VERSION ""

NS_ :

BS_:

BU_: RAND MM5 STMM DD PDM BMS PM VCU
VAL_TABLE_ contactorState 2 "Open" 1 "Close" 0 "Faulted" ;
VAL_TABLE_ vehicleState 8 "Faulted" 7 "ReadyToMove" 6 "Standby" 5 "PrechargeComplete" 4 "PrechargeTimeout" 3 "Precharge" 2 "PrechargeReady" 1 "StartDelay" 0 "Off" ;

BO_ 554 RAND_554: 8 RAND
 SG_ RAND_rateZHor : 32|16@1- (0.02,0) [-655.36|655.34] "degps" Vector__XXX
 SG_ RAND_rateYHor : 16|16@1- (0.02,0) [-655.36|655.34] "degps" Vector__XXX
 SG_ RAND_rateXHor : 0|16@1- (0.02,0) [-655.36|655.34] "degps" Vector__XXX

BO_ 553 RAND_553: 8 RAND
 SG_ RAND_accZHor : 32|16@1- (0.02,0) [-655.36|655.34] "mps2" Vector__XXX
 SG_ RAND_accYHor : 16|16@1- (0.02,0) [-655.36|655.34] "mps2" Vector__XXX
 SG_ RAND_accXHor : 0|16@1- (0.02,0) [-655.36|655.34] "mps2" Vector__XXX

BO_ 552 RAND_552: 8 RAND
 SG_ RAND_pitch : 16|16@1- (0.003,0) [-98.304|98.301] "deg" Vector__XXX
 SG_ RAND_roll : 0|16@1- (0.003,0) [-98.304|98.301] "deg" Vector__XXX

BO_ 551 RAND_551: 8 RAND
 SG_ RAND_accCPoi : 48|16@1- (0.02,0) [-655.36|655.34] "mps2" Vector__XXX
 SG_ RAND_radiusPoi : 32|16@1- (0.01,0) [-327.68|327.67] "m" Vector__XXX
 SG_ RAND_distAPoi : 0|32@1- (0.001,0) [-2147483.648|2147483.647] "m" Vector__XXX

BO_ 550 RAND_550: 8 Vector__XXX
 SG_ RAND_angSPoi : 48|16@1- (0.003,0) [-98.304|98.301] "deg" Vector__XXX
 SG_ RAND_velAPoi : 32|16@1- (0.02,0) [-655.36|655.34] "kph" Vector__XXX
 SG_ RAND_velYPoi : 16|16@1- (0.02,0) [-655.36|655.34] "kph" Vector__XXX
 SG_ RAND_velXPoi : 0|16@1- (0.02,0) [-655.36|655.34] "kph" Vector__XXX

BO_ 501 RAND_501: 8 RAND
 SG_ RAND_postRadPres : 32|16@1- (0.1,0) [-3276.8|3276.7] "kPa" Vector__XXX
 SG_ RAND_postRadTemp : 16|16@1- (0.1,0) [-3276.8|3276.7] "degC" Vector__XXX
 SG_ RAND_counterMsg501 : 0|4@1+ (1,0) [0|15] "" Vector__XXX

BO_ 500 RAND_500: 8 RAND
 SG_ RAND_preRadPres : 32|16@1- (0.1,0) [-3276.8|3276.7] "kPa" Vector__XXX
 SG_ RAND_preRadTemp : 16|16@1- (0.1,0) [-3276.8|3276.7] "degC" Vector__XXX
 SG_ RAND_counterMsg500 : 0|4@1+ (1,0) [0|15] "" Vector__XXX

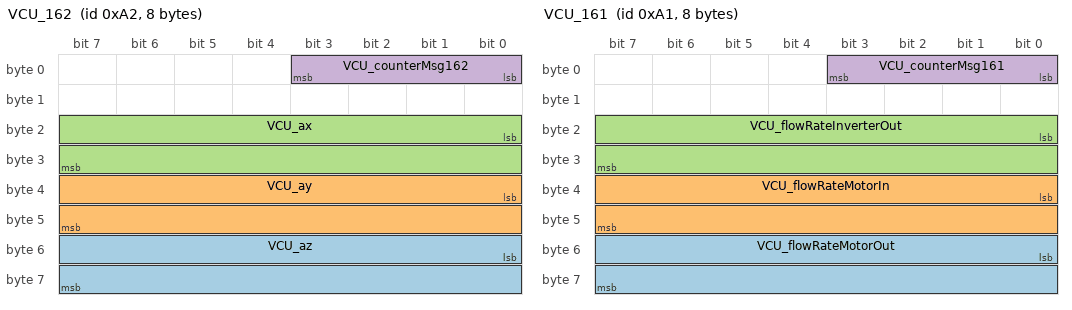
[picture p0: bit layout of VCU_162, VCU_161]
BO_ 162 VCU_162: 8 VCU
 SG_ VCU_az : 48|16@1- (0.001,0) [-32.768|32.767] "g" Vector__XXX
 SG_ VCU_ay : 32|16@1- (0.001,0) [-32.768|32.767] "g" Vector__XXX
 SG_ VCU_ax : 16|16@1- (0.001,0) [-32.768|32.767] "g" Vector__XXX
 SG_ VCU_counterMsg162 : 0|4@1+ (1,0) [0|15] "" Vector__XXX

BO_ 161 VCU_161: 8 VCU
 SG_ VCU_flowRateMotorOut : 48|16@1- (0.1,0) [-3276.8|3276.7] "lpm" Vector__XXX
 SG_ VCU_flowRateMotorIn : 32|16@1- (0.1,0) [-3276.8|3276.7] "lpm" Vector__XXX
 SG_ VCU_flowRateInverterOut : 16|16@1- (0.1,0) [-3276.8|3276.7] "lpm" Vector__XXX
 SG_ VCU_counterMsg161 : 0|4@1+ (1,0) [0|15] "" Vector__XXX

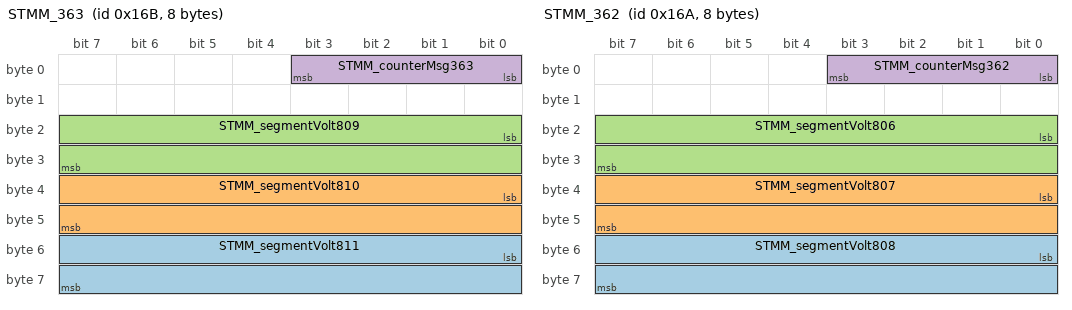
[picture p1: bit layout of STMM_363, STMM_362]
BO_ 363 STMM_363: 8 STMM
 SG_ STMM_segmentVolt811 : 48|16@1- (0.001,0) [-32.768|32.767] "V" Vector__XXX
 SG_ STMM_segmentVolt810 : 32|16@1- (0.001,0) [-32.768|32.767] "V" Vector__XXX
 SG_ STMM_segmentVolt809 : 16|16@1- (0.001,0) [-32.768|32.767] "V" Vector__XXX
 SG_ STMM_counterMsg363 : 0|4@1+ (1,0) [0|15] "" Vector__XXX

BO_ 362 STMM_362: 8 STMM
 SG_ STMM_segmentVolt808 : 48|16@1- (0.001,0) [-32.768|32.767] "V" Vector__XXX
 SG_ STMM_segmentVolt807 : 32|16@1- (0.001,0) [-32.768|32.767] "V" Vector__XXX
 SG_ STMM_segmentVolt806 : 16|16@1- (0.001,0) [-32.768|32.767] "V" Vector__XXX
 SG_ STMM_counterMsg362 : 0|4@1+ (1,0) [0|15] "" Vector__XXX

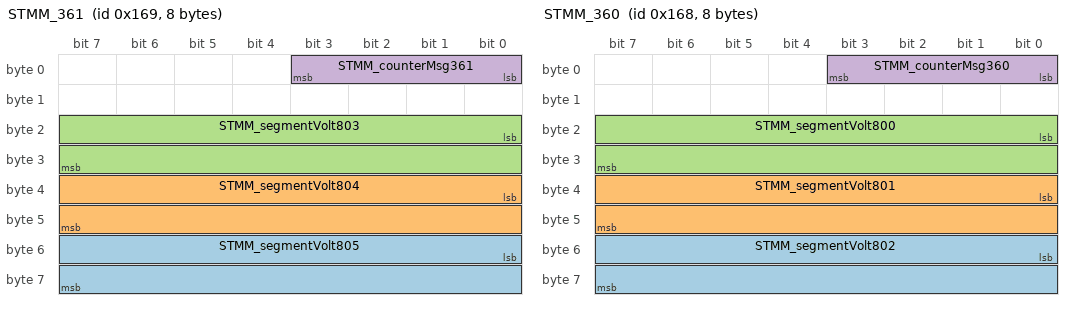
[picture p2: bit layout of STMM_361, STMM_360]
BO_ 361 STMM_361: 8 STMM
 SG_ STMM_segmentVolt805 : 48|16@1- (0.001,0) [-32.768|32.767] "V" Vector__XXX
 SG_ STMM_segmentVolt804 : 32|16@1- (0.001,0) [-32.768|32.767] "V" Vector__XXX
 SG_ STMM_segmentVolt803 : 16|16@1- (0.001,0) [-32.768|32.767] "V" Vector__XXX
 SG_ STMM_counterMsg361 : 0|4@1+ (1,0) [0|15] "" Vector__XXX

BO_ 360 STMM_360: 8 STMM
 SG_ STMM_segmentVolt802 : 48|16@1- (0.001,0) [-32.768|32.767] "V" Vector__XXX
 SG_ STMM_segmentVolt801 : 32|16@1- (0.001,0) [-32.768|32.767] "V" Vector__XXX
 SG_ STMM_segmentVolt800 : 16|16@1- (0.001,0) [-32.768|32.767] "V" Vector__XXX
 SG_ STMM_counterMsg360 : 0|4@1+ (1,0) [0|15] "" Vector__XXX

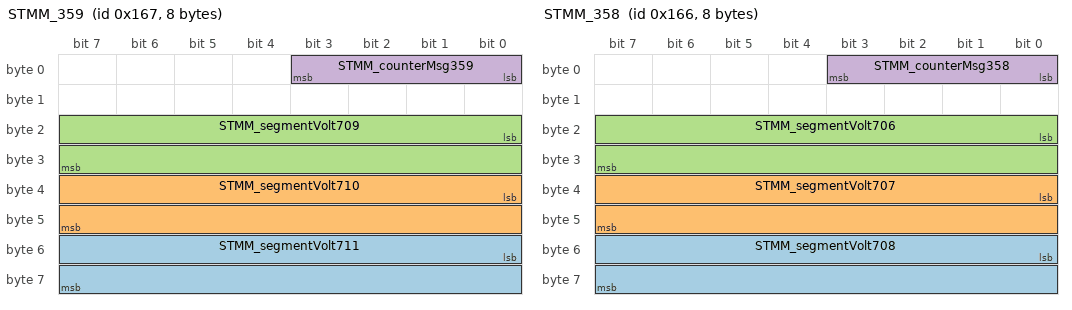
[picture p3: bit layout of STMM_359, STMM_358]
BO_ 359 STMM_359: 8 STMM
 SG_ STMM_segmentVolt711 : 48|16@1- (0.001,0) [-32.768|32.767] "V" Vector__XXX
 SG_ STMM_segmentVolt710 : 32|16@1- (0.001,0) [-32.768|32.767] "V" Vector__XXX
 SG_ STMM_segmentVolt709 : 16|16@1- (0.001,0) [-32.768|32.767] "V" Vector__XXX
 SG_ STMM_counterMsg359 : 0|4@1+ (1,0) [0|15] "" Vector__XXX

BO_ 358 STMM_358: 8 STMM
 SG_ STMM_segmentVolt708 : 48|16@1- (0.001,0) [-32.768|32.767] "V" Vector__XXX
 SG_ STMM_segmentVolt707 : 32|16@1- (0.001,0) [-32.768|32.767] "V" Vector__XXX
 SG_ STMM_segmentVolt706 : 16|16@1- (0.001,0) [-32.768|32.767] "V" Vector__XXX
 SG_ STMM_counterMsg358 : 0|4@1+ (1,0) [0|15] "" Vector__XXX

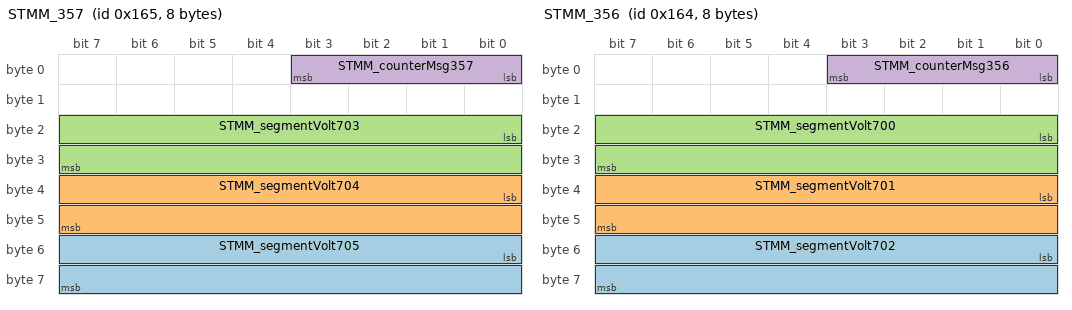
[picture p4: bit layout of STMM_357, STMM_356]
BO_ 357 STMM_357: 8 STMM
 SG_ STMM_segmentVolt705 : 48|16@1- (0.001,0) [-32.768|32.767] "V" Vector__XXX
 SG_ STMM_segmentVolt704 : 32|16@1- (0.001,0) [-32.768|32.767] "V" Vector__XXX
 SG_ STMM_segmentVolt703 : 16|16@1- (0.001,0) [-32.768|32.767] "V" Vector__XXX
 SG_ STMM_counterMsg357 : 0|4@1+ (1,0) [0|15] "" Vector__XXX

BO_ 356 STMM_356: 8 STMM
 SG_ STMM_segmentVolt702 : 48|16@1- (0.001,0) [-32.768|32.767] "V" Vector__XXX
 SG_ STMM_segmentVolt701 : 32|16@1- (0.001,0) [-32.768|32.767] "V" Vector__XXX
 SG_ STMM_segmentVolt700 : 16|16@1- (0.001,0) [-32.768|32.767] "V" Vector__XXX
 SG_ STMM_counterMsg356 : 0|4@1+ (1,0) [0|15] "" Vector__XXX

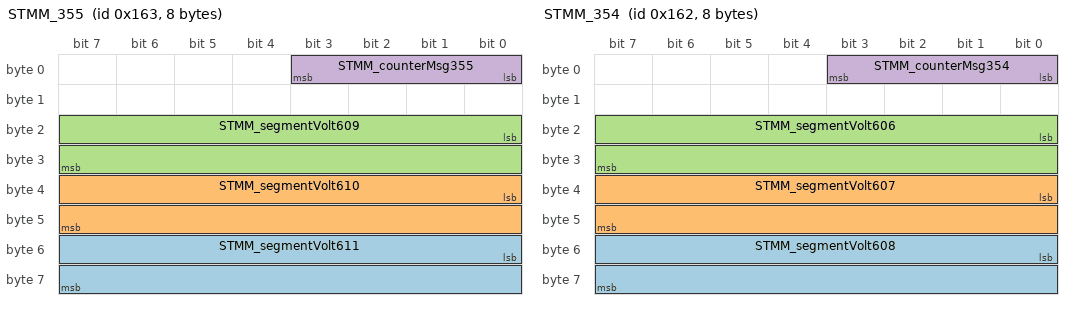
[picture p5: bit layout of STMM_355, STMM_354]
BO_ 355 STMM_355: 8 STMM
 SG_ STMM_segmentVolt611 : 48|16@1- (0.001,0) [-32.768|32.767] "V" Vector__XXX
 SG_ STMM_segmentVolt610 : 32|16@1- (0.001,0) [-32.768|32.767] "V" Vector__XXX
 SG_ STMM_segmentVolt609 : 16|16@1- (0.001,0) [-32.768|32.767] "V" Vector__XXX
 SG_ STMM_counterMsg355 : 0|4@1+ (1,0) [0|15] "" Vector__XXX

BO_ 354 STMM_354: 8 STMM
 SG_ STMM_segmentVolt608 : 48|16@1- (0.001,0) [-32.768|32.767] "V" Vector__XXX
 SG_ STMM_segmentVolt607 : 32|16@1- (0.001,0) [-32.768|32.767] "V" Vector__XXX
 SG_ STMM_segmentVolt606 : 16|16@1- (0.001,0) [-32.768|32.767] "V" Vector__XXX
 SG_ STMM_counterMsg354 : 0|4@1+ (1,0) [0|15] "" Vector__XXX

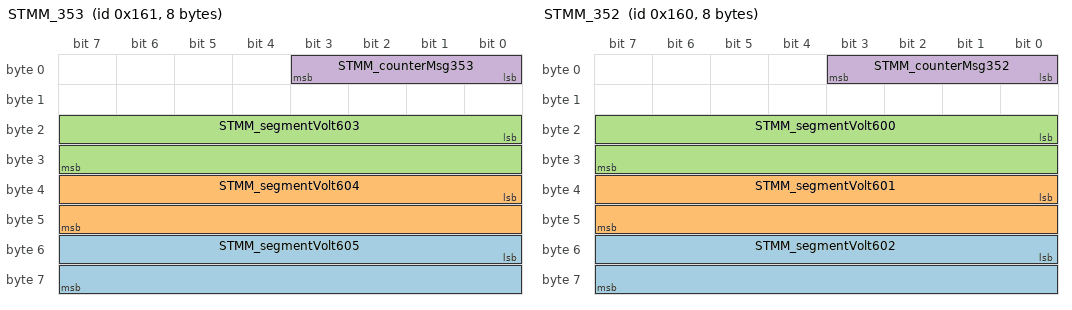
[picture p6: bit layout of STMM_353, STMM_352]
BO_ 353 STMM_353: 8 STMM
 SG_ STMM_segmentVolt605 : 48|16@1- (0.001,0) [-32.768|32.767] "V" Vector__XXX
 SG_ STMM_segmentVolt604 : 32|16@1- (0.001,0) [-32.768|32.767] "V" Vector__XXX
 SG_ STMM_segmentVolt603 : 16|16@1- (0.001,0) [-32.768|32.767] "V" Vector__XXX
 SG_ STMM_counterMsg353 : 0|4@1+ (1,0) [0|15] "" Vector__XXX

BO_ 352 STMM_352: 8 STMM
 SG_ STMM_segmentVolt602 : 48|16@1- (0.001,0) [-32.768|32.767] "V" Vector__XXX
 SG_ STMM_segmentVolt601 : 32|16@1- (0.001,0) [-32.768|32.767] "V" Vector__XXX
 SG_ STMM_segmentVolt600 : 16|16@1- (0.001,0) [-32.768|32.767] "V" Vector__XXX
 SG_ STMM_counterMsg352 : 0|4@1+ (1,0) [0|15] "" Vector__XXX

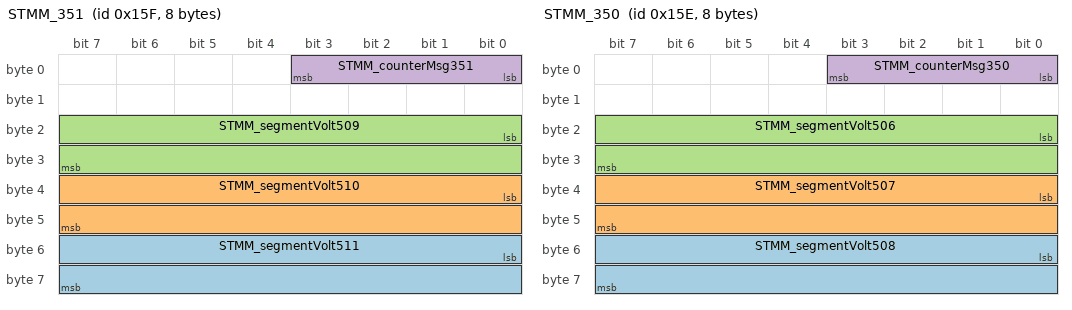
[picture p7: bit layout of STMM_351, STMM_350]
BO_ 351 STMM_351: 8 STMM
 SG_ STMM_segmentVolt511 : 48|16@1- (0.001,0) [-32.768|32.767] "V" Vector__XXX
 SG_ STMM_segmentVolt510 : 32|16@1- (0.001,0) [-32.768|32.767] "V" Vector__XXX
 SG_ STMM_segmentVolt509 : 16|16@1- (0.001,0) [-32.768|32.767] "V" Vector__XXX
 SG_ STMM_counterMsg351 : 0|4@1+ (1,0) [0|15] "" Vector__XXX

BO_ 350 STMM_350: 8 STMM
 SG_ STMM_segmentVolt508 : 48|16@1- (0.001,0) [-32.768|32.767] "V" Vector__XXX
 SG_ STMM_segmentVolt507 : 32|16@1- (0.001,0) [-32.768|32.767] "V" Vector__XXX
 SG_ STMM_segmentVolt506 : 16|16@1- (0.001,0) [-32.768|32.767] "V" Vector__XXX
 SG_ STMM_counterMsg350 : 0|4@1+ (1,0) [0|15] "" Vector__XXX

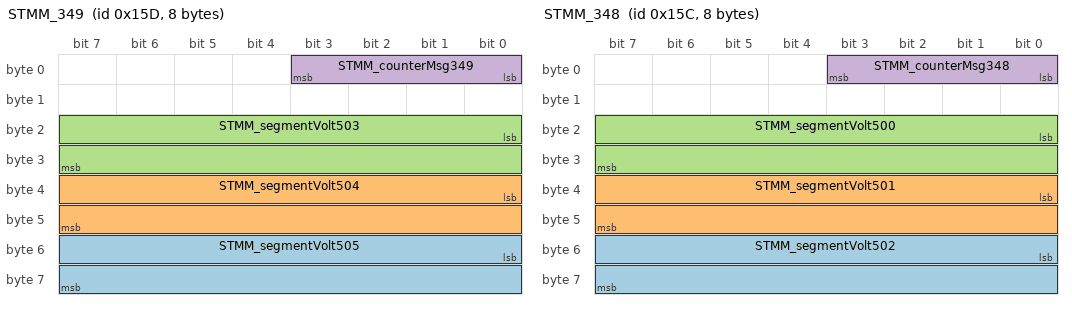
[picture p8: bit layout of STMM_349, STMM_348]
BO_ 349 STMM_349: 8 STMM
 SG_ STMM_segmentVolt505 : 48|16@1- (0.001,0) [-32.768|32.767] "V" Vector__XXX
 SG_ STMM_segmentVolt504 : 32|16@1- (0.001,0) [-32.768|32.767] "V" Vector__XXX
 SG_ STMM_segmentVolt503 : 16|16@1- (0.001,0) [-32.768|32.767] "V" Vector__XXX
 SG_ STMM_counterMsg349 : 0|4@1+ (1,0) [0|15] "" Vector__XXX

BO_ 348 STMM_348: 8 STMM
 SG_ STMM_segmentVolt502 : 48|16@1- (0.001,0) [-32.768|32.767] "V" Vector__XXX
 SG_ STMM_segmentVolt501 : 32|16@1- (0.001,0) [-32.768|32.767] "V" Vector__XXX
 SG_ STMM_segmentVolt500 : 16|16@1- (0.001,0) [-32.768|32.767] "V" Vector__XXX
 SG_ STMM_counterMsg348 : 0|4@1+ (1,0) [0|15] "" Vector__XXX

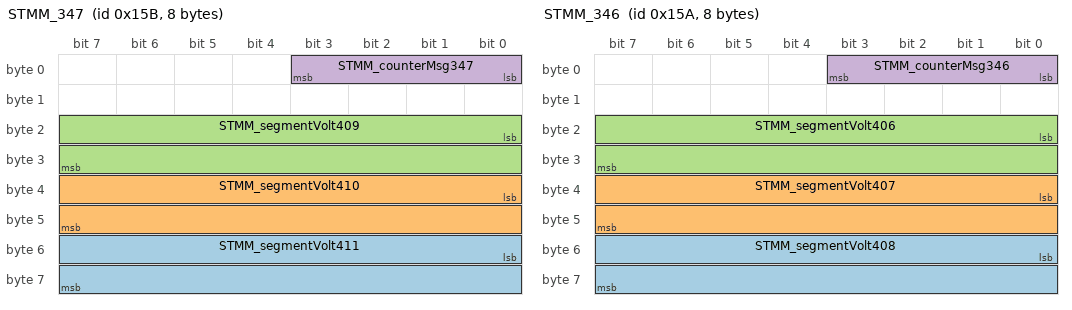
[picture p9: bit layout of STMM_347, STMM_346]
BO_ 347 STMM_347: 8 STMM
 SG_ STMM_segmentVolt411 : 48|16@1- (0.001,0) [-32.768|32.767] "V" Vector__XXX
 SG_ STMM_segmentVolt410 : 32|16@1- (0.001,0) [-32.768|32.767] "V" Vector__XXX
 SG_ STMM_segmentVolt409 : 16|16@1- (0.001,0) [-32.768|32.767] "V" Vector__XXX
 SG_ STMM_counterMsg347 : 0|4@1+ (1,0) [0|15] "" Vector__XXX

BO_ 346 STMM_346: 8 STMM
 SG_ STMM_segmentVolt408 : 48|16@1- (0.001,0) [-32.768|32.767] "V" Vector__XXX
 SG_ STMM_segmentVolt407 : 32|16@1- (0.001,0) [-32.768|32.767] "V" Vector__XXX
 SG_ STMM_segmentVolt406 : 16|16@1- (0.001,0) [-32.768|32.767] "V" Vector__XXX
 SG_ STMM_counterMsg346 : 0|4@1+ (1,0) [0|15] "" Vector__XXX

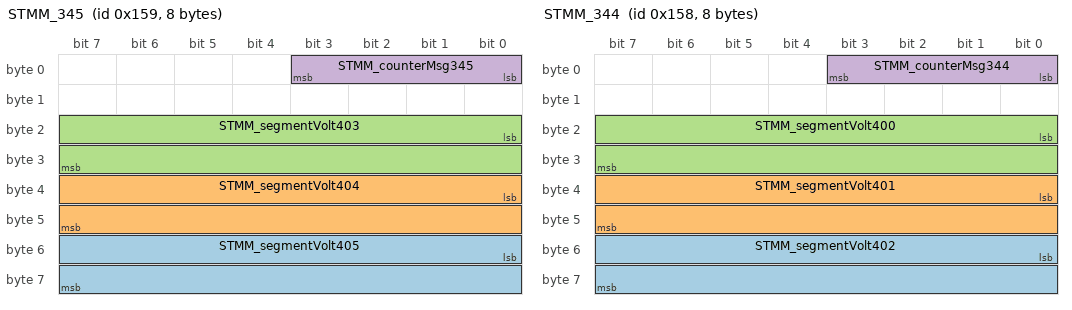
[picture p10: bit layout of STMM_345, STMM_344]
BO_ 345 STMM_345: 8 STMM
 SG_ STMM_segmentVolt405 : 48|16@1- (0.001,0) [-32.768|32.767] "V" Vector__XXX
 SG_ STMM_segmentVolt404 : 32|16@1- (0.001,0) [-32.768|32.767] "V" Vector__XXX
 SG_ STMM_segmentVolt403 : 16|16@1- (0.001,0) [-32.768|32.767] "V" Vector__XXX
 SG_ STMM_counterMsg345 : 0|4@1+ (1,0) [0|15] "" Vector__XXX

BO_ 344 STMM_344: 8 STMM
 SG_ STMM_segmentVolt402 : 48|16@1- (0.001,0) [-32.768|32.767] "V" Vector__XXX
 SG_ STMM_segmentVolt401 : 32|16@1- (0.001,0) [-32.768|32.767] "V" Vector__XXX
 SG_ STMM_segmentVolt400 : 16|16@1- (0.001,0) [-32.768|32.767] "V" Vector__XXX
 SG_ STMM_counterMsg344 : 0|4@1+ (1,0) [0|15] "" Vector__XXX

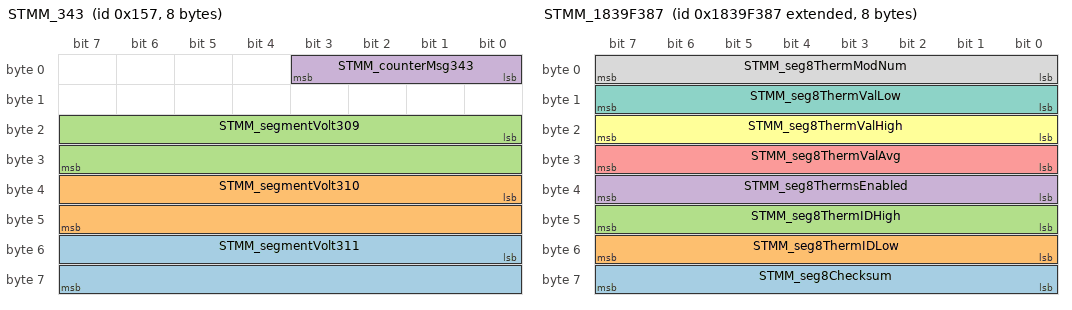
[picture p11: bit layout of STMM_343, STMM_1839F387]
BO_ 343 STMM_343: 8 STMM
 SG_ STMM_segmentVolt311 : 48|16@1- (0.001,0) [-32.768|32.767] "V" Vector__XXX
 SG_ STMM_segmentVolt310 : 32|16@1- (0.001,0) [-32.768|32.767] "V" Vector__XXX
 SG_ STMM_segmentVolt309 : 16|16@1- (0.001,0) [-32.768|32.767] "V" Vector__XXX
 SG_ STMM_counterMsg343 : 0|4@1+ (1,0) [0|15] "" Vector__XXX

BO_ 342 STMM_342: 8 STMM
 SG_ STMM_segmentVolt308 : 48|16@1- (0.001,0) [-32.768|32.767] "V" Vector__XXX
 SG_ STMM_segmentVolt307 : 32|16@1- (0.001,0) [-32.768|32.767] "V" Vector__XXX
 SG_ STMM_segmentVolt306 : 16|16@1- (0.001,0) [-32.768|32.767] "V" Vector__XXX
 SG_ STMM_counterMsg342 : 0|4@1+ (1,0) [0|15] "" Vector__XXX

BO_ 341 STMM_341: 8 STMM
 SG_ STMM_segmentVolt305 : 48|16@1- (0.001,0) [-32.768|32.767] "V" Vector__XXX
 SG_ STMM_segmentVolt304 : 32|16@1- (0.001,0) [-32.768|32.767] "V" Vector__XXX
 SG_ STMM_segmentVolt303 : 16|16@1- (0.001,0) [-32.768|32.767] "V" Vector__XXX
 SG_ STMM_counterMsg341 : 0|4@1+ (1,0) [0|15] "" Vector__XXX

BO_ 340 STMM_340: 8 STMM
 SG_ STMM_segmentVolt302 : 48|16@1- (0.001,0) [-32.768|32.767] "V" Vector__XXX
 SG_ STMM_segmentVolt301 : 32|16@1- (0.001,0) [-32.768|32.767] "V" Vector__XXX
 SG_ STMM_segmentVolt300 : 16|16@1- (0.001,0) [-32.768|32.767] "V" Vector__XXX
 SG_ STMM_counterMsg340 : 0|4@1+ (1,0) [0|15] "" Vector__XXX

BO_ 339 STMM_339: 8 STMM
 SG_ STMM_segmentVolt211 : 48|16@1- (0.001,0) [-32.768|32.767] "V" Vector__XXX
 SG_ STMM_segmentVolt210 : 32|16@1- (0.001,0) [-32.768|32.767] "V" Vector__XXX
 SG_ STMM_segmentVolt209 : 16|16@1- (0.001,0) [-32.768|32.767] "V" Vector__XXX
 SG_ STMM_counterMsg339 : 0|4@1+ (1,0) [0|15] "" Vector__XXX

BO_ 338 STMM_338: 8 STMM
 SG_ STMM_segmentVolt208 : 48|16@1- (0.001,0) [-32.768|32.767] "V" Vector__XXX
 SG_ STMM_segmentVolt207 : 32|16@1- (0.001,0) [-32.768|32.767] "V" Vector__XXX
 SG_ STMM_segmentVolt206 : 16|16@1- (0.001,0) [-32.768|32.767] "V" Vector__XXX
 SG_ STMM_counterMsg338 : 0|4@1+ (1,0) [0|15] "" Vector__XXX

BO_ 337 STMM_337: 8 STMM
 SG_ STMM_segmentVolt205 : 48|16@1- (0.001,0) [-32.768|32.767] "V" Vector__XXX
 SG_ STMM_segmentVolt204 : 32|16@1- (0.001,0) [-32.768|32.767] "V" Vector__XXX
 SG_ STMM_segmentVolt203 : 16|16@1- (0.001,0) [-32.768|32.767] "V" Vector__XXX
 SG_ STMM_counterMsg337 : 0|4@1+ (1,0) [0|15] "" Vector__XXX

BO_ 336 STMM_336: 8 STMM
 SG_ STMM_segmentVolt202 : 48|16@1- (0.001,0) [-32.768|32.767] "V" Vector__XXX
 SG_ STMM_segmentVolt201 : 32|16@1- (0.001,0) [-32.768|32.767] "V" Vector__XXX
 SG_ STMM_segmentVolt200 : 16|16@1- (0.001,0) [-32.768|32.767] "V" Vector__XXX
 SG_ STMM_counterMsg336 : 0|4@1+ (1,0) [0|15] "" Vector__XXX

BO_ 335 STMM_335: 8 STMM
 SG_ STMM_segmentVolt111 : 48|16@1- (0.001,0) [-32.768|32.767] "V" Vector__XXX
 SG_ STMM_segmentVolt110 : 32|16@1- (0.001,0) [-32.768|32.767] "V" Vector__XXX
 SG_ STMM_segmentVolt109 : 16|16@1- (0.001,0) [-32.768|32.767] "V" Vector__XXX
 SG_ STMM_counterMsg335 : 0|4@1+ (1,0) [0|15] "" Vector__XXX

BO_ 334 STMM_334: 8 STMM
 SG_ STMM_segmentVolt108 : 48|16@1- (0.001,0) [-32.768|32.767] "V" Vector__XXX
 SG_ STMM_segmentVolt107 : 32|16@1- (0.001,0) [-32.768|32.767] "V" Vector__XXX
 SG_ STMM_segmentVolt106 : 16|16@1- (0.001,0) [-32.768|32.767] "V" Vector__XXX
 SG_ STMM_counterMsg334 : 0|4@1+ (1,0) [0|15] "" Vector__XXX

BO_ 333 STMM_333: 8 STMM
 SG_ STMM_segmentVolt105 : 48|16@1- (0.001,0) [-32.768|32.767] "V" Vector__XXX
 SG_ STMM_segmentVolt104 : 32|16@1- (0.001,0) [-32.768|32.767] "V" Vector__XXX
 SG_ STMM_segmentVolt103 : 16|16@1- (0.001,0) [-32.768|32.767] "V" Vector__XXX
 SG_ STMM_counterMsg333 : 0|4@1+ (1,0) [0|15] "" Vector__XXX

BO_ 332 STMM_332: 8 STMM
 SG_ STMM_segmentVolt102 : 48|16@1- (0.001,0) [-32.768|32.767] "V" Vector__XXX
 SG_ STMM_segmentVolt101 : 32|16@1- (0.001,0) [-32.768|32.767] "V" Vector__XXX
 SG_ STMM_segmentVolt100 : 16|16@1- (0.001,0) [-32.768|32.767] "V" Vector__XXX
 SG_ STMM_counterMsg332 : 0|4@1+ (1,0) [0|15] "" Vector__XXX

BO_ 299 STMM_299: 8 STMM
 SG_ STMM_counterMsg299 : 0|4@1+ (1,0) [0|15] "" Vector__XXX
 SG_ STMM_segmentSync : 16|8@1+ (1,0) [0|1] "" Vector__XXX

BO_ 160 VCU_160: 8 VCU
 SG_ VCU_driveSpeed : 16|16@1- (0.1,0) [-32768|32767] "mph" Vector__XXX
 SG_ VCU_counterMsg160 : 0|4@1+ (1,0) [0|15] "" Vector__XXX

BO_ 159 VCU_159: 8 VCU
 SG_ VCU_tireTempRRO : 48|16@1- (0.1,0) [-3276.8|3276.7] "degC" Vector__XXX
 SG_ VCU_tireTempRRM : 32|16@1- (0.1,0) [-3276.8|3276.7] "degC" Vector__XXX
 SG_ VCU_tireTempRRI : 16|16@1- (0.1,0) [-3276.8|3276.7] "degC" Vector__XXX
 SG_ VCU_counterMsg159 : 0|4@1+ (1,0) [0|15] "" Vector__XXX

BO_ 158 VCU_158: 8 VCU
 SG_ VCU_tireTempRLO : 48|16@1- (0.1,0) [-3276.8|3276.7] "degC" Vector__XXX
 SG_ VCU_tireTempRLM : 32|16@1- (0.1,0) [-3276.8|3276.7] "degC" Vector__XXX
 SG_ VCU_tireTempRLI : 16|16@1- (0.1,0) [-3276.8|3276.7] "degC" Vector__XXX
 SG_ VCU_counterMsg158 : 0|4@1+ (1,0) [0|15] "" Vector__XXX

BO_ 157 VCU_157: 8 VCU
 SG_ VCU_tireTempFRO : 48|16@1- (0.1,0) [-3276.8|3276.7] "degC" Vector__XXX
 SG_ VCU_tireTempFRM : 32|16@1- (0.1,0) [-3276.8|3276.7] "degC" Vector__XXX
 SG_ VCU_tireTempFRI : 16|16@1- (0.1,0) [-3276.8|3276.7] "degC" Vector__XXX
 SG_ VCU_counterMsg157 : 0|4@1+ (1,0) [0|15] "" Vector__XXX

BO_ 156 VCU_156: 8 VCU
 SG_ VCU_tireTempFLO : 48|16@1- (0.1,0) [-3276.8|3276.7] "degC" Vector__XXX
 SG_ VCU_tireTempFLM : 32|16@1- (0.1,0) [-3276.8|3276.7] "degC" Vector__XXX
 SG_ VCU_tireTempFLI : 16|16@1- (0.1,0) [-3276.8|3276.7] "degC" Vector__XXX
 SG_ VCU_counterMsg156 : 0|4@1+ (1,0) [0|15] "" Vector__XXX

BO_ 155 VCU_155: 8 VCU
 SG_ VCU_rotorTempRR : 32|16@1- (0.1,0) [-3276.8|3276.7] "degC" Vector__XXX
 SG_ VCU_rotorTempRL : 16|16@1- (0.1,0) [-3276.8|3276.7] "degC" Vector__XXX
 SG_ VCU_counterMsg155 : 0|4@1+ (1,0) [0|15] "" Vector__XXX

BO_ 154 VCU_154: 8 VCU
 SG_ VCU_rotorTempFR : 32|16@1- (0.1,0) [-3276.8|3276.7] "degC" Vector__XXX
 SG_ VCU_rotorTempFL : 16|16@1- (0.1,0) [-3276.8|3276.7] "degC" Vector__XXX
 SG_ VCU_counterMsg154 : 0|4@1+ (1,0) [0|15] "" Vector__XXX

BO_ 2553934727 STMM_1839F387: 8 STMM
 SG_ STMM_seg8Checksum : 56|8@1+ (1,0) [0|255] "" Vector__XXX
 SG_ STMM_seg8ThermIDLow : 48|8@1+ (1,0) [0|255] "" Vector__XXX
 SG_ STMM_seg8ThermIDHigh : 40|8@1+ (1,0) [0|255] "" Vector__XXX
 SG_ STMM_seg8ThermsEnabled : 32|8@1+ (1,0) [0|255] "" Vector__XXX
 SG_ STMM_seg8ThermValAvg : 24|8@1- (1,0) [-128|127] "degC" Vector__XXX
 SG_ STMM_seg8ThermValHigh : 16|8@1- (1,0) [-128|127] "degC" Vector__XXX
 SG_ STMM_seg8ThermValLow : 8|8@1- (1,0) [-128|127] "degC" Vector__XXX
 SG_ STMM_seg8ThermModNum : 0|8@1+ (1,0) [0|255] "" Vector__XXX

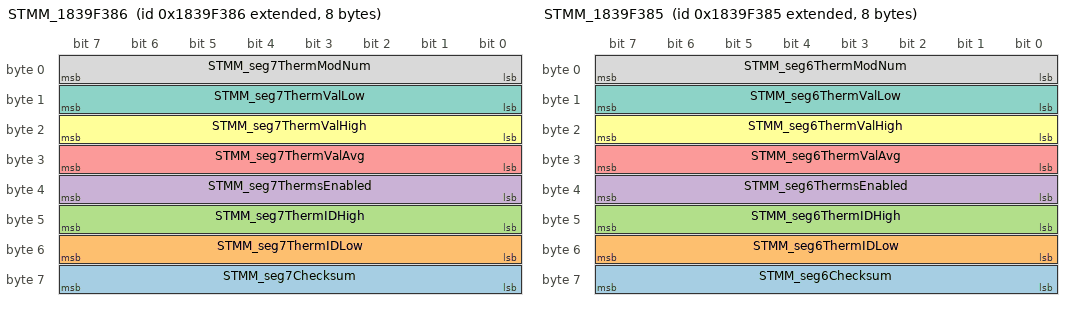
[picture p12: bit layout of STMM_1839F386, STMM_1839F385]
BO_ 2553934726 STMM_1839F386: 8 STMM
 SG_ STMM_seg7Checksum : 56|8@1+ (1,0) [0|255] "" Vector__XXX
 SG_ STMM_seg7ThermIDLow : 48|8@1+ (1,0) [0|255] "" Vector__XXX
 SG_ STMM_seg7ThermIDHigh : 40|8@1+ (1,0) [0|255] "" Vector__XXX
 SG_ STMM_seg7ThermsEnabled : 32|8@1+ (1,0) [0|255] "" Vector__XXX
 SG_ STMM_seg7ThermValAvg : 24|8@1- (1,0) [-128|127] "degC" Vector__XXX
 SG_ STMM_seg7ThermValHigh : 16|8@1- (1,0) [-128|127] "degC" Vector__XXX
 SG_ STMM_seg7ThermValLow : 8|8@1- (1,0) [-128|127] "degC" Vector__XXX
 SG_ STMM_seg7ThermModNum : 0|8@1+ (1,0) [0|255] "" Vector__XXX

BO_ 2553934725 STMM_1839F385: 8 STMM
 SG_ STMM_seg6Checksum : 56|8@1+ (1,0) [0|255] "" Vector__XXX
 SG_ STMM_seg6ThermIDLow : 48|8@1+ (1,0) [0|255] "" Vector__XXX
 SG_ STMM_seg6ThermIDHigh : 40|8@1+ (1,0) [0|255] "" Vector__XXX
 SG_ STMM_seg6ThermsEnabled : 32|8@1+ (1,0) [0|255] "" Vector__XXX
 SG_ STMM_seg6ThermValAvg : 24|8@1- (1,0) [-128|127] "degC" Vector__XXX
 SG_ STMM_seg6ThermValHigh : 16|8@1- (1,0) [-128|127] "degC" Vector__XXX
 SG_ STMM_seg6ThermValLow : 8|8@1- (1,0) [-128|127] "degC" Vector__XXX
 SG_ STMM_seg6ThermModNum : 0|8@1+ (1,0) [0|255] "" Vector__XXX

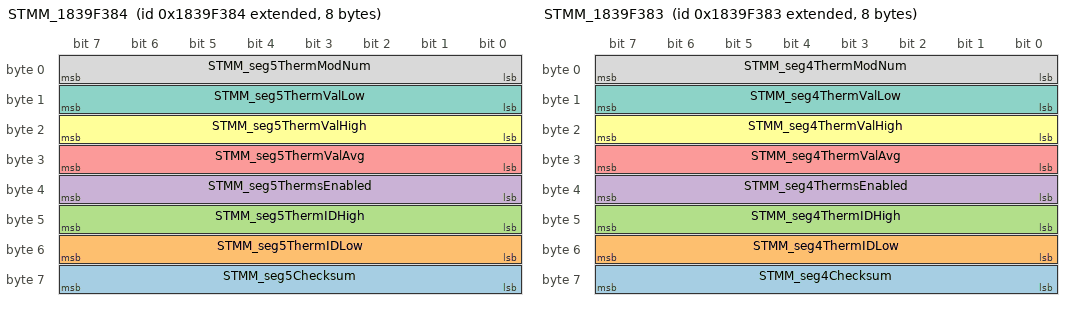
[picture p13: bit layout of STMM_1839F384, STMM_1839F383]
BO_ 2553934724 STMM_1839F384: 8 STMM
 SG_ STMM_seg5Checksum : 56|8@1+ (1,0) [0|255] "" Vector__XXX
 SG_ STMM_seg5ThermIDLow : 48|8@1+ (1,0) [0|255] "" Vector__XXX
 SG_ STMM_seg5ThermIDHigh : 40|8@1+ (1,0) [0|255] "" Vector__XXX
 SG_ STMM_seg5ThermsEnabled : 32|8@1+ (1,0) [0|255] "" Vector__XXX
 SG_ STMM_seg5ThermValAvg : 24|8@1- (1,0) [-128|127] "degC" Vector__XXX
 SG_ STMM_seg5ThermValHigh : 16|8@1- (1,0) [-128|127] "degC" Vector__XXX
 SG_ STMM_seg5ThermValLow : 8|8@1- (1,0) [-128|127] "degC" Vector__XXX
 SG_ STMM_seg5ThermModNum : 0|8@1+ (1,0) [0|255] "" Vector__XXX

BO_ 2553934723 STMM_1839F383: 8 STMM
 SG_ STMM_seg4Checksum : 56|8@1+ (1,0) [0|255] "" Vector__XXX
 SG_ STMM_seg4ThermIDLow : 48|8@1+ (1,0) [0|255] "" Vector__XXX
 SG_ STMM_seg4ThermIDHigh : 40|8@1+ (1,0) [0|255] "" Vector__XXX
 SG_ STMM_seg4ThermsEnabled : 32|8@1+ (1,0) [0|255] "" Vector__XXX
 SG_ STMM_seg4ThermValAvg : 24|8@1- (1,0) [-128|127] "degC" Vector__XXX
 SG_ STMM_seg4ThermValHigh : 16|8@1- (1,0) [-128|127] "degC" Vector__XXX
 SG_ STMM_seg4ThermValLow : 8|8@1- (1,0) [-128|127] "degC" Vector__XXX
 SG_ STMM_seg4ThermModNum : 0|8@1+ (1,0) [0|255] "" Vector__XXX

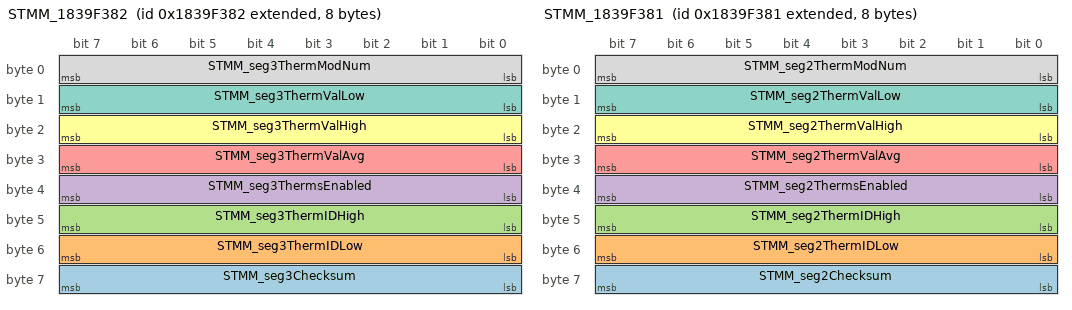
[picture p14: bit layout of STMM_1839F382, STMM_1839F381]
BO_ 2553934722 STMM_1839F382: 8 STMM
 SG_ STMM_seg3Checksum : 56|8@1+ (1,0) [0|255] "" Vector__XXX
 SG_ STMM_seg3ThermIDLow : 48|8@1+ (1,0) [0|255] "" Vector__XXX
 SG_ STMM_seg3ThermIDHigh : 40|8@1+ (1,0) [0|255] "" Vector__XXX
 SG_ STMM_seg3ThermsEnabled : 32|8@1+ (1,0) [0|255] "" Vector__XXX
 SG_ STMM_seg3ThermValAvg : 24|8@1- (1,0) [-128|127] "degC" Vector__XXX
 SG_ STMM_seg3ThermValHigh : 16|8@1- (1,0) [-128|127] "degC" Vector__XXX
 SG_ STMM_seg3ThermValLow : 8|8@1- (1,0) [-128|127] "degC" Vector__XXX
 SG_ STMM_seg3ThermModNum : 0|8@1+ (1,0) [0|255] "" Vector__XXX

BO_ 2553934721 STMM_1839F381: 8 STMM
 SG_ STMM_seg2Checksum : 56|8@1+ (1,0) [0|255] "" Vector__XXX
 SG_ STMM_seg2ThermIDLow : 48|8@1+ (1,0) [0|255] "" Vector__XXX
 SG_ STMM_seg2ThermIDHigh : 40|8@1+ (1,0) [0|255] "" Vector__XXX
 SG_ STMM_seg2ThermsEnabled : 32|8@1+ (1,0) [0|255] "" Vector__XXX
 SG_ STMM_seg2ThermValAvg : 24|8@1- (1,0) [-128|127] "degC" Vector__XXX
 SG_ STMM_seg2ThermValHigh : 16|8@1- (1,0) [-128|127] "degC" Vector__XXX
 SG_ STMM_seg2ThermValLow : 8|8@1- (1,0) [-128|127] "degC" Vector__XXX
 SG_ STMM_seg2ThermModNum : 0|8@1+ (1,0) [0|255] "" Vector__XXX

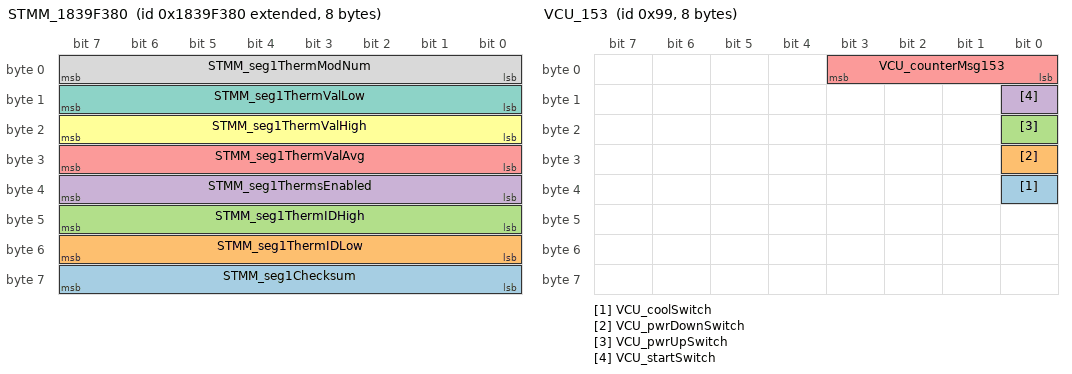
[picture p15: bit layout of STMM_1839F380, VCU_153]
BO_ 2553934720 STMM_1839F380: 8 STMM
 SG_ STMM_seg1Checksum : 56|8@1+ (1,0) [0|255] "" Vector__XXX
 SG_ STMM_seg1ThermIDLow : 48|8@1+ (1,0) [0|255] "" Vector__XXX
 SG_ STMM_seg1ThermIDHigh : 40|8@1+ (1,0) [0|255] "" Vector__XXX
 SG_ STMM_seg1ThermsEnabled : 32|8@1+ (1,0) [0|255] "" Vector__XXX
 SG_ STMM_seg1ThermValAvg : 24|8@1- (1,0) [-128|127] "degC" Vector__XXX
 SG_ STMM_seg1ThermValHigh : 16|8@1- (1,0) [-128|127] "degC" Vector__XXX
 SG_ STMM_seg1ThermValLow : 8|8@1- (1,0) [-128|127] "degC" Vector__XXX
 SG_ STMM_seg1ThermModNum : 0|8@1+ (1,0) [0|255] "" Vector__XXX

BO_ 153 VCU_153: 8 VCU
 SG_ VCU_coolSwitch : 32|1@1+ (1,0) [0|1] "" Vector__XXX
 SG_ VCU_pwrDownSwitch : 24|1@1+ (1,0) [0|1] "" Vector__XXX
 SG_ VCU_pwrUpSwitch : 16|1@1+ (1,0) [0|1] "" Vector__XXX
 SG_ VCU_startSwitch : 8|1@1+ (1,0) [0|1] "" Vector__XXX
 SG_ VCU_counterMsg153 : 0|4@1+ (1,0) [0|15] "" Vector__XXX

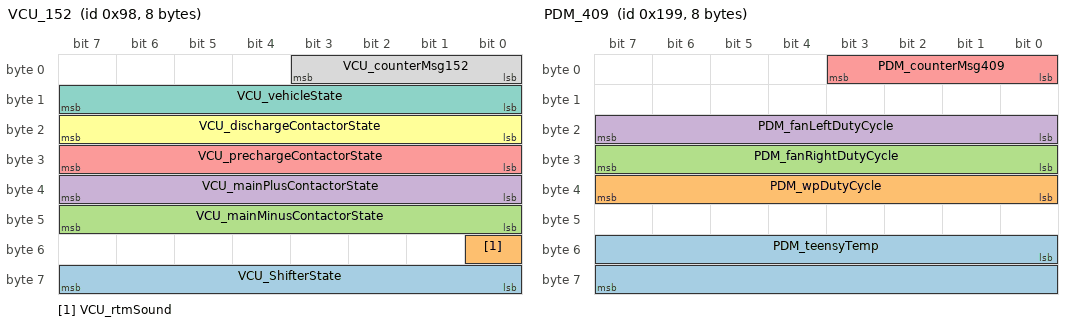
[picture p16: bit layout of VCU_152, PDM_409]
BO_ 152 VCU_152: 8 VCU
 SG_ VCU_ShifterState : 56|8@1+ (1,0) [0|255] "" Vector__XXX
 SG_ VCU_rtmSound : 48|1@1+ (1,0) [0|1] "" Vector__XXX
 SG_ VCU_mainMinusContactorState : 40|8@1+ (1,0) [0|255] "" Vector__XXX
 SG_ VCU_mainPlusContactorState : 32|8@1+ (1,0) [0|255] "" Vector__XXX
 SG_ VCU_prechargeContactorState : 24|8@1+ (1,0) [0|255] "" Vector__XXX
 SG_ VCU_dischargeContactorState : 16|8@1+ (1,0) [0|255] "" Vector__XXX
 SG_ VCU_vehicleState : 8|8@1+ (1,0) [0|255] "" Vector__XXX
 SG_ VCU_counterMsg152 : 0|4@1+ (1,0) [0|15] "" Vector__XXX

BO_ 151 VCU_151: 8 VCU
 SG_ VCU_brakePressureR : 48|16@1- (0.1,0) [0|2000] "psi" Vector__XXX
 SG_ VCU_brakePressureF : 32|16@1- (0.1,0) [0|2000] "psi" Vector__XXX
 SG_ VCU_brakeBias : 16|16@1- (0.1,0) [-3276.8|3276.7] "%" Vector__XXX
 SG_ VCU_counterMsg151 : 0|4@1+ (1,0) [0|15] "" Vector__XXX

BO_ 380 MM5_380: 8 MM5
 SG_ MM5_az : 32|16@1+ (-0.0001274,4.1745795) [-4.1745795|4.1745795] "g" Vector__XXX

BO_ 376 MM5_376: 8 MM5
 SG_ MM5_rollRate : 0|16@1+ (-0.005,163.9) [-163.775|163.9] "deg/s" Vector__XXX
 SG_ MM5_ax : 32|16@1+ (-0.0001274,4.1745795) [-4.1745795|4.1745795] "g" Vector__XXX

BO_ 372 MM5_372: 8 MM5
 SG_ MM5_yawRate : 0|16@1+ (0.005,-163.9) [-163.9|163.775] "deg/s" Vector__XXX
 SG_ MM5_ay : 32|16@1+ (0.0001274,-4.1745795) [-4.1745795|4.1745795] "g" Vector__XXX

BO_ 331 STMM_331: 8 STMM
 SG_ STMM_segmentTemp811 : 48|16@1- (0.1,0) [-5|120] "degC" Vector__XXX
 SG_ STMM_segmentTemp810 : 32|16@1- (0.1,0) [-5|120] "degC" Vector__XXX
 SG_ STMM_segmentTemp809 : 16|16@1- (0.1,0) [-5|120] "degC" Vector__XXX
 SG_ STMM_counterMsg331 : 0|4@1+ (1,0) [0|15] "" Vector__XXX

BO_ 330 STMM_330: 8 STMM
 SG_ STMM_segmentTemp808 : 48|16@1- (0.1,0) [-5|120] "degC" Vector__XXX
 SG_ STMM_segmentTemp807 : 32|16@1- (0.1,0) [-5|120] "degC" Vector__XXX
 SG_ STMM_segmentTemp806 : 16|16@1- (0.1,0) [-5|120] "degC" Vector__XXX
 SG_ STMM_counterMsg330 : 0|4@1+ (1,0) [0|15] "" Vector__XXX

BO_ 329 STMM_329: 8 STMM
 SG_ STMM_segmentTemp805 : 48|16@1- (0.1,0) [-5|120] "degC" Vector__XXX
 SG_ STMM_segmentTemp804 : 32|16@1- (0.1,0) [-5|120] "degC" Vector__XXX
 SG_ STMM_segmentTemp803 : 16|16@1- (0.1,0) [-5|120] "degC" Vector__XXX
 SG_ STMM_counterMsg329 : 0|4@1+ (1,0) [0|15] "" Vector__XXX

BO_ 328 STMM_328: 8 STMM
 SG_ STMM_segmentTemp802 : 48|16@1- (0.1,0) [-5|120] "degC" Vector__XXX
 SG_ STMM_segmentTemp801 : 32|16@1- (0.1,0) [-5|120] "degC" Vector__XXX
 SG_ STMM_segmentTemp800 : 16|16@1- (0.1,0) [-5|120] "degC" Vector__XXX
 SG_ STMM_counterMsg328 : 0|4@1+ (1,0) [0|15] "" Vector__XXX

BO_ 327 STMM_327: 8 STMM
 SG_ STMM_segmentTemp711 : 48|16@1- (0.1,0) [-5|120] "degC" Vector__XXX
 SG_ STMM_segmentTemp710 : 32|16@1- (0.1,0) [-5|120] "degC" Vector__XXX
 SG_ STMM_segmentTemp709 : 16|16@1- (0.1,0) [-5|120] "degC" Vector__XXX
 SG_ STMM_counterMsg327 : 0|4@1+ (1,0) [0|15] "" Vector__XXX

BO_ 326 STMM_326: 8 STMM
 SG_ STMM_segmentTemp708 : 48|16@1- (0.1,0) [-5|120] "degC" Vector__XXX
 SG_ STMM_segmentTemp707 : 32|16@1- (0.1,0) [-5|120] "degC" Vector__XXX
 SG_ STMM_segmentTemp706 : 16|16@1- (0.1,0) [-5|120] "degC" Vector__XXX
 SG_ STMM_counterMsg326 : 0|4@1+ (1,0) [0|15] "" Vector__XXX

BO_ 325 STMM_325: 8 STMM
 SG_ STMM_segmentTemp705 : 48|16@1- (0.1,0) [-5|120] "degC" Vector__XXX
 SG_ STMM_segmentTemp704 : 32|16@1- (0.1,0) [-5|120] "degC" Vector__XXX
 SG_ STMM_segmentTemp703 : 16|16@1- (0.1,0) [-5|120] "degC" Vector__XXX
 SG_ STMM_counterMsg325 : 0|4@1+ (1,0) [0|15] "" Vector__XXX

BO_ 324 STMM_324: 8 STMM
 SG_ STMM_segmentTemp702 : 48|16@1- (0.1,0) [-5|120] "degC" Vector__XXX
 SG_ STMM_segmentTemp701 : 32|16@1- (0.1,0) [-5|120] "degC" Vector__XXX
 SG_ STMM_segmentTemp700 : 16|16@1- (0.1,0) [-5|120] "degC" Vector__XXX
 SG_ STMM_counterMsg324 : 0|4@1+ (1,0) [0|15] "" Vector__XXX

BO_ 323 STMM_323: 8 STMM
 SG_ STMM_segmentTemp611 : 48|16@1- (0.1,0) [-5|120] "degC" Vector__XXX
 SG_ STMM_segmentTemp610 : 32|16@1- (0.1,0) [-5|120] "degC" Vector__XXX
 SG_ STMM_segmentTemp609 : 16|16@1- (0.1,0) [-5|120] "degC" Vector__XXX
 SG_ STMM_counterMsg323 : 0|4@1+ (1,0) [0|15] "" Vector__XXX

BO_ 322 STMM_322: 8 STMM
 SG_ STMM_segmentTemp608 : 48|16@1- (0.1,0) [-5|120] "degC" Vector__XXX
 SG_ STMM_segmentTemp607 : 32|16@1- (0.1,0) [-5|120] "degC" Vector__XXX
 SG_ STMM_segmentTemp606 : 16|16@1- (0.1,0) [-5|120] "degC" Vector__XXX
 SG_ STMM_counterMsg322 : 0|4@1+ (1,0) [0|15] "" Vector__XXX

BO_ 321 STMM_321: 8 STMM
 SG_ STMM_segmentTemp605 : 48|16@1- (0.1,0) [-5|120] "degC" Vector__XXX
 SG_ STMM_segmentTemp604 : 32|16@1- (0.1,0) [-5|120] "degC" Vector__XXX
 SG_ STMM_segmentTemp603 : 16|16@1- (0.1,0) [-5|120] "degC" Vector__XXX
 SG_ STMM_counterMsg321 : 0|4@1+ (1,0) [0|15] "" Vector__XXX

BO_ 320 STMM_320: 8 STMM
 SG_ STMM_segmentTemp602 : 48|16@1- (0.1,0) [-5|120] "degC" Vector__XXX
 SG_ STMM_segmentTemp601 : 32|16@1- (0.1,0) [-5|120] "degC" Vector__XXX
 SG_ STMM_segmentTemp600 : 16|16@1- (0.1,0) [-5|120] "degC" Vector__XXX
 SG_ STMM_counterMsg320 : 0|4@1+ (1,0) [0|15] "" Vector__XXX

BO_ 319 STMM_319: 8 STMM
 SG_ STMM_segmentTemp511 : 48|16@1- (0.1,0) [-5|120] "degC" Vector__XXX
 SG_ STMM_segmentTemp510 : 32|16@1- (0.1,0) [-5|120] "degC" Vector__XXX
 SG_ STMM_segmentTemp509 : 16|16@1- (0.1,0) [-5|120] "degC" Vector__XXX
 SG_ STMM_counterMsg319 : 0|4@1+ (1,0) [0|15] "" Vector__XXX

BO_ 318 STMM_318: 8 STMM
 SG_ STMM_segmentTemp508 : 48|16@1- (0.1,0) [-5|120] "degC" Vector__XXX
 SG_ STMM_segmentTemp507 : 32|16@1- (0.1,0) [-5|120] "degC" Vector__XXX
 SG_ STMM_segmentTemp506 : 16|16@1- (0.1,0) [-5|120] "degC" Vector__XXX
 SG_ STMM_counterMsg318 : 0|4@1+ (1,0) [0|15] "" Vector__XXX

BO_ 317 STMM_317: 8 STMM
 SG_ STMM_segmentTemp505 : 48|16@1- (0.1,0) [-5|120] "degC" Vector__XXX
 SG_ STMM_segmentTemp504 : 32|16@1- (0.1,0) [-5|120] "degC" Vector__XXX
 SG_ STMM_segmentTemp503 : 16|16@1- (0.1,0) [-5|120] "degC" Vector__XXX
 SG_ STMM_counterMsg317 : 0|4@1+ (1,0) [0|15] "" Vector__XXX

BO_ 316 STMM_316: 8 STMM
 SG_ STMM_segmentTemp502 : 48|16@1- (0.1,0) [-5|120] "degC" Vector__XXX
 SG_ STMM_segmentTemp501 : 32|16@1- (0.1,0) [-5|120] "degC" Vector__XXX
 SG_ STMM_segmentTemp500 : 16|16@1- (0.1,0) [-5|120] "degC" Vector__XXX
 SG_ STMM_counterMsg316 : 0|4@1+ (1,0) [0|15] "" Vector__XXX

BO_ 315 STMM_315: 8 STMM
 SG_ STMM_segmentTemp411 : 48|16@1- (0.1,0) [-5|120] "degC" Vector__XXX
 SG_ STMM_segmentTemp410 : 32|16@1- (0.1,0) [-5|120] "degC" Vector__XXX
 SG_ STMM_segmentTemp409 : 16|16@1- (0.1,0) [-5|120] "degC" Vector__XXX
 SG_ STMM_counterMsg315 : 0|4@1+ (1,0) [0|15] "" Vector__XXX

BO_ 314 STMM_314: 8 STMM
 SG_ STMM_segmentTemp408 : 48|16@1- (0.1,0) [-5|120] "degC" Vector__XXX
 SG_ STMM_segmentTemp407 : 32|16@1- (0.1,0) [-5|120] "degC" Vector__XXX
 SG_ STMM_segmentTemp406 : 16|16@1- (0.1,0) [-5|120] "degC" Vector__XXX
 SG_ STMM_counterMsg314 : 0|4@1+ (1,0) [0|15] "" Vector__XXX

BO_ 313 STMM_313: 8 STMM
 SG_ STMM_segmentTemp405 : 48|16@1- (0.1,0) [-5|120] "degC" Vector__XXX
 SG_ STMM_segmentTemp404 : 32|16@1- (0.1,0) [-5|120] "degC" Vector__XXX
 SG_ STMM_segmentTemp403 : 16|16@1- (0.1,0) [-5|120] "degC" Vector__XXX
 SG_ STMM_counterMsg313 : 0|4@1+ (1,0) [0|15] "" Vector__XXX

BO_ 312 STMM_312: 8 STMM
 SG_ STMM_segmentTemp402 : 48|16@1- (0.1,0) [-5|120] "degC" Vector__XXX
 SG_ STMM_segmentTemp401 : 32|16@1- (0.1,0) [-5|120] "degC" Vector__XXX
 SG_ STMM_segmentTemp400 : 16|16@1- (0.1,0) [-5|120] "degC" Vector__XXX
 SG_ STMM_counterMsg312 : 0|4@1+ (1,0) [0|15] "" Vector__XXX

BO_ 311 STMM_311: 8 STMM
 SG_ STMM_segmentTemp311 : 48|16@1- (0.1,0) [-5|120] "degC" Vector__XXX
 SG_ STMM_segmentTemp310 : 32|16@1- (0.1,0) [-5|120] "degC" Vector__XXX
 SG_ STMM_segmentTemp309 : 16|16@1- (0.1,0) [-5|120] "degC" Vector__XXX
 SG_ STMM_counterMsg311 : 0|4@1+ (1,0) [0|15] "" Vector__XXX

BO_ 310 STMM_310: 8 STMM
 SG_ STMM_segmentTemp308 : 48|16@1- (0.1,0) [-5|120] "degC" Vector__XXX
 SG_ STMM_segmentTemp307 : 32|16@1- (0.1,0) [-5|120] "degC" Vector__XXX
 SG_ STMM_segmentTemp306 : 16|16@1- (0.1,0) [-5|120] "degC" Vector__XXX
 SG_ STMM_counterMsg310 : 0|4@1+ (1,0) [0|15] "" Vector__XXX

BO_ 309 STMM_309: 8 STMM
 SG_ STMM_segmentTemp305 : 48|16@1- (0.1,0) [-5|120] "degC" Vector__XXX
 SG_ STMM_segmentTemp304 : 32|16@1- (0.1,0) [-5|120] "degC" Vector__XXX
 SG_ STMM_segmentTemp303 : 16|16@1- (0.1,0) [-5|120] "degC" Vector__XXX
 SG_ STMM_counterMsg309 : 0|4@1+ (1,0) [0|15] "" Vector__XXX

BO_ 308 STMM_308: 8 STMM
 SG_ STMM_segmentTemp302 : 48|16@1- (0.1,0) [-5|120] "degC" Vector__XXX
 SG_ STMM_segmentTemp301 : 32|16@1- (0.1,0) [-5|120] "degC" Vector__XXX
 SG_ STMM_segmentTemp300 : 16|16@1- (0.1,0) [-5|120] "degC" Vector__XXX
 SG_ STMM_counterMsg308 : 0|4@1+ (1,0) [0|15] "" Vector__XXX

BO_ 307 STMM_307: 8 STMM
 SG_ STMM_segmentTemp211 : 48|16@1- (0.1,0) [-5|120] "degC" Vector__XXX
 SG_ STMM_segmentTemp210 : 32|16@1- (0.1,0) [-5|120] "degC" Vector__XXX
 SG_ STMM_segmentTemp209 : 16|16@1- (0.1,0) [-5|120] "degC" Vector__XXX
 SG_ STMM_counterMsg307 : 0|4@1+ (1,0) [0|15] "" Vector__XXX

BO_ 306 STMM_306: 8 STMM
 SG_ STMM_segmentTemp208 : 48|16@1- (0.1,0) [-5|120] "degC" Vector__XXX
 SG_ STMM_segmentTemp207 : 32|16@1- (0.1,0) [-5|120] "degC" Vector__XXX
 SG_ STMM_segmentTemp206 : 16|16@1- (0.1,0) [-5|120] "degC" Vector__XXX
 SG_ STMM_counterMsg306 : 0|4@1+ (1,0) [0|15] "" Vector__XXX

BO_ 305 STMM_305: 8 STMM
 SG_ STMM_segmentTemp205 : 48|16@1- (0.1,0) [-5|120] "degC" Vector__XXX
 SG_ STMM_segmentTemp204 : 32|16@1- (0.1,0) [-5|120] "degC" Vector__XXX
 SG_ STMM_segmentTemp203 : 16|16@1- (0.1,0) [-5|120] "degC" Vector__XXX
 SG_ STMM_counterMsg305 : 0|4@1+ (1,0) [0|15] "" Vector__XXX

BO_ 304 STMM_304: 8 STMM
 SG_ STMM_segmentTemp202 : 48|16@1- (0.1,0) [-5|120] "degC" Vector__XXX
 SG_ STMM_segmentTemp201 : 32|16@1- (0.1,0) [-5|120] "degC" Vector__XXX
 SG_ STMM_segmentTemp200 : 16|16@1- (0.1,0) [-5|120] "degC" Vector__XXX
 SG_ STMM_counterMsg304 : 0|4@1+ (1,0) [0|15] "" Vector__XXX

BO_ 303 STMM_303: 8 STMM
 SG_ STMM_segmentTemp111 : 48|16@1- (0.1,0) [-5|120] "degC" Vector__XXX
 SG_ STMM_segmentTemp110 : 32|16@1- (0.1,0) [-5|120] "degC" Vector__XXX
 SG_ STMM_segmentTemp109 : 16|16@1- (0.1,0) [-5|120] "degC" Vector__XXX
 SG_ STMM_counterMsg303 : 0|4@1+ (1,0) [0|15] "" Vector__XXX

BO_ 302 STMM_302: 8 STMM
 SG_ STMM_segmentTemp108 : 48|16@1- (0.1,0) [-5|120] "degC" Vector__XXX
 SG_ STMM_segmentTemp107 : 32|16@1- (0.1,0) [-5|120] "degC" Vector__XXX
 SG_ STMM_segmentTemp106 : 16|16@1- (0.1,0) [-5|120] "degC" Vector__XXX
 SG_ STMM_counterMsg302 : 0|4@1+ (1,0) [0|15] "" Vector__XXX

BO_ 301 STMM_301: 8 STMM
 SG_ STMM_segmentTemp105 : 48|16@1- (0.1,0) [-5|120] "degC" Vector__XXX
 SG_ STMM_segmentTemp104 : 32|16@1- (0.1,0) [-5|120] "degC" Vector__XXX
 SG_ STMM_segmentTemp103 : 16|16@1- (0.1,0) [-5|120] "degC" Vector__XXX
 SG_ STMM_counterMsg301 : 0|4@1+ (1,0) [0|15] "" Vector__XXX

BO_ 300 STMM_300: 8 STMM
 SG_ STMM_segmentTemp102 : 48|16@1- (0.1,0) [-5|120] "degC" Vector__XXX
 SG_ STMM_segmentTemp101 : 32|16@1- (0.1,0) [-5|120] "degC" Vector__XXX
 SG_ STMM_segmentTemp100 : 16|16@1- (0.1,0) [-5|120] "degC" Vector__XXX
 SG_ STMM_counterMsg300 : 0|4@1+ (1,0) [0|15] "" Vector__XXX

BO_ 250 DD_250: 8 DD
 SG_ DD_teensyTemp : 32|16@1- (0.1,0) [0|150] "degC" Vector__XXX
 SG_ DD_counterMsg250 : 0|4@1+ (1,0) [0|15] "" Vector__XXX
 SG_ DD_boardTemp : 16|16@1- (0.1,0) [0|150] "degC" Vector__XXX

BO_ 414 PDM_414: 8 PDM
 SG_ PDM_runtimeMinutes : 48|16@1- (1,0) [-32768|32767] "mins" Vector__XXX
 SG_ PDM_runtimeHours : 32|16@1- (1,0) [-32768|32767] "hrs" Vector__XXX
 SG_ PDM_counterMsg414 : 0|4@1+ (1,0) [0|15] "" Vector__XXX
 SG_ PDM_carMiles : 16|16@1- (0.1,0) [-3276.8|3276.7] "mi" Vector__XXX

BO_ 413 PDM_413: 8 PDM
 SG_ PDM_keepAliveVoltMin : 48|16@1- (0.001,0) [-32.768|32.767] "V" Vector__XXX
 SG_ PDM_keepAliveVoltMax : 32|16@1- (0.001,0) [-32.768|32.767] "V" Vector__XXX
 SG_ PDM_keepAliveVoltAvg : 16|16@1- (0.001,0) [-32.768|32.767] "V" Vector__XXX
 SG_ PDM_counterMsg413 : 0|4@1+ (1,0) [0|15] "" Vector__XXX

BO_ 412 PDM_412: 8 PDM
 SG_ PDM_dataVoltMin : 48|16@1- (0.001,0) [-32.768|32.767] "V" Vector__XXX
 SG_ PDM_dataVoltMax : 32|16@1- (0.001,0) [-32.768|32.767] "V" Vector__XXX
 SG_ PDM_dataVoltAvg : 16|16@1- (0.001,0) [-32.768|32.767] "V" Vector__XXX
 SG_ PDM_counterMsg412 : 0|4@1+ (1,0) [0|15] "" Vector__XXX

BO_ 411 PDM_411: 8 PDM
 SG_ PDM_glvVoltMin : 48|16@1- (0.001,0) [-32.768|32.767] "V" Vector__XXX
 SG_ PDM_glvVoltMax : 32|16@1- (0.001,0) [-32.768|32.767] "V" Vector__XXX
 SG_ PDM_glvVoltAvg : 16|16@1- (0.001,0) [-32.768|32.767] "V" Vector__XXX
 SG_ PDM_counterMsg411 : 0|4@1+ (1,0) [0|15] "" Vector__XXX

BO_ 410 PDM_410: 8 PDM
 SG_ PDM_uptime : 0|32@1+ (1,0) [0|4294967295] "ms" Vector__XXX

BO_ 409 PDM_409: 8 PDM
 SG_ PDM_teensyTemp : 48|16@1- (0.1,0) [-5|100] "degC" Vector__XXX
 SG_ PDM_wpDutyCycle : 32|8@1+ (1,0) [0|100] "%" Vector__XXX
 SG_ PDM_fanRightDutyCycle : 24|8@1+ (1,0) [0|100] "%" Vector__XXX
 SG_ PDM_fanLeftDutyCycle : 16|8@1+ (1,0) [0|100] "%" Vector__XXX
 SG_ PDM_counterMsg409 : 0|4@1+ (1,0) [0|15] "" Vector__XXX

BO_ 408 PDM_408: 8 PDM
 SG_ PDM_wpVoltMin : 48|16@1- (0.001,0) [-32.768|32.767] "V" Vector__XXX
 SG_ PDM_wpVoltMax : 32|16@1- (0.001,0) [-32.768|32.767] "V" Vector__XXX
 SG_ PDM_wpVoltAvg : 16|16@1- (0.001,0) [-32.768|32.767] "V" Vector__XXX
 SG_ PDM_counterMsg408 : 0|4@1+ (1,0) [0|15] "" Vector__XXX

BO_ 407 PDM_407: 8 PDM
 SG_ PDM_wpCurrentMin : 48|16@1- (0.01,0) [-327.68|327.67] "A" Vector__XXX
 SG_ PDM_wpCurrentMax : 32|16@1- (0.01,0) [-327.68|327.67] "A" Vector__XXX
 SG_ PDM_wpCurrentAvg : 16|16@1- (0.01,0) [-327.68|327.67] "A" Vector__XXX
 SG_ PDM_counterMsg407 : 0|4@1+ (1,0) [0|15] "" Vector__XXX

BO_ 406 PDM_406: 8 PDM
 SG_ PDM_fanLeftVoltMin : 48|16@1- (0.001,0) [-32.768|32.767] "V" Vector__XXX
 SG_ PDM_fanLeftVoltMax : 32|16@1- (0.001,0) [-32.768|32.767] "V" Vector__XXX
 SG_ PDM_fanLeftVoltAvg : 16|16@1- (0.001,0) [-32.768|32.767] "V" Vector__XXX
 SG_ PDM_counterMsg406 : 0|4@1+ (1,0) [0|15] "" Vector__XXX

BO_ 405 PDM_405: 8 PDM
 SG_ PDM_fanLeftCurrentMin : 48|16@1- (0.01,0) [-327.68|327.67] "A" Vector__XXX
 SG_ PDM_fanLeftCurrentMax : 32|16@1- (0.01,0) [-327.68|327.67] "A" Vector__XXX
 SG_ PDM_fanLeftCurrentAvg : 16|16@1- (0.01,0) [-327.68|327.67] "A" Vector__XXX
 SG_ PDM_counterMsg405 : 0|4@1+ (1,0) [0|15] "" Vector__XXX

BO_ 404 PDM_404: 8 PDM
 SG_ PDM_fanRightVoltMin : 48|16@1- (0.001,0) [-32.768|32.767] "V" Vector__XXX
 SG_ PDM_fanRightVoltMax : 32|16@1- (0.001,0) [-32.768|32.767] "V" Vector__XXX
 SG_ PDM_fanRightVoltAvg : 16|16@1- (0.001,0) [-32.768|32.767] "V" Vector__XXX
 SG_ PDM_counterMsg404 : 0|4@1+ (1,0) [0|15] "" Vector__XXX

BO_ 403 PDM_403: 8 PDM
 SG_ PDM_fanRightCurrentMin : 48|16@1- (0.01,0) [-327.68|327.67] "A" Vector__XXX
 SG_ PDM_fanRightCurrentMax : 32|16@1- (0.01,0) [-327.68|327.67] "A" Vector__XXX
 SG_ PDM_fanRightCurrentAvg : 16|16@1- (0.01,0) [-327.68|327.67] "A" Vector__XXX
 SG_ PDM_counterMsg403 : 0|4@1+ (1,0) [0|15] "" Vector__XXX

BO_ 402 PDM_402: 8 PDM
 SG_ PDM_pdmVoltMin : 48|16@1- (0.001,0) [-32.768|32.767] "V" Vector__XXX
 SG_ PDM_pdmVoltMax : 32|16@1- (0.001,0) [-32.768|32.767] "V" Vector__XXX
 SG_ PDM_pdmVoltAvg : 16|16@1- (0.001,0) [-32.768|32.767] "V" Vector__XXX
 SG_ PDM_counterMsg402 : 0|4@1+ (1,0) [0|15] "" Vector__XXX

BO_ 401 PDM_401: 8 PDM
 SG_ PDM_pdmCurrentMin : 48|16@1- (0.01,0) [-327.68|327.67] "A" Vector__XXX
 SG_ PDM_pdmCurrentMax : 32|16@1- (0.01,0) [-327.68|327.67] "A" Vector__XXX
 SG_ PDM_pdmCurrentAvg : 16|16@1- (0.01,0) [-327.68|327.67] "A" Vector__XXX
 SG_ PDM_counterMsg401 : 0|4@1+ (1,0) [0|15] "" Vector__XXX

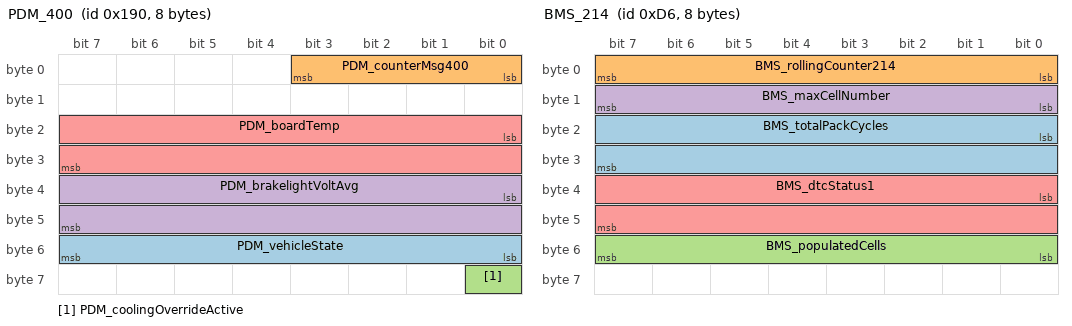
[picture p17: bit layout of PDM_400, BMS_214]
BO_ 400 PDM_400: 8 PDM
 SG_ PDM_vehicleState : 48|8@1+ (1,0) [0|255] "" Vector__XXX
 SG_ PDM_counterMsg400 : 0|4@1+ (1,0) [0|15] "" Vector__XXX
 SG_ PDM_coolingOverrideActive : 56|1@1+ (1,0) [0|1] "" Vector__XXX
 SG_ PDM_brakelightVoltAvg : 32|16@1- (0.001,0) [-32.768|32.767] "V" Vector__XXX
 SG_ PDM_boardTemp : 16|16@1- (0.1,0) [-5|100] "degC" Vector__XXX

BO_ 215 BMS_215: 8 BMS
 SG_ BMS_rollingCounter215 : 0|8@1+ (1,0) [0|255] "" Vector__XXX
 SG_ BMS_relayState : 16|16@1+ (1,0) [0|65535] "" Vector__XXX
 SG_ BMS_failsafeStatus : 32|16@1+ (1,0) [0|65535] "" Vector__XXX
 SG_ BMS_dtcStatus2 : 48|16@1+ (1,0) [0|65535] "" Vector__XXX

BO_ 214 BMS_214: 8 BMS
 SG_ BMS_totalPackCycles : 16|16@1+ (1,0) [0|65535] "Cycle" Vector__XXX
 SG_ BMS_rollingCounter214 : 0|8@1+ (1,0) [0|255] "" Vector__XXX
 SG_ BMS_populatedCells : 48|8@1+ (1,0) [0|255] "" Vector__XXX
 SG_ BMS_maxCellNumber : 8|8@1+ (1,0) [0|255] "" Vector__XXX
 SG_ BMS_dtcStatus1 : 32|16@1+ (1,0) [0|65535] "" Vector__XXX

BO_ 213 BMS_213: 8 BMS
 SG_ BMS_rollingCounter213 : 0|8@1+ (1,0) [0|255] "" Vector__XXX
 SG_ BMS_currLimStatus : 48|16@1+ (1,0) [0|65535] "" Vector__XXX
 SG_ BMS_adaptiveTotalCapacity : 16|16@1- (0.1,0) [-3276.8|3276.7] "Ahr" Vector__XXX
 SG_ BMS_adaptiveAmphours : 32|16@1- (0.1,0) [-3276.8|3276.7] "Ahr" Vector__XXX

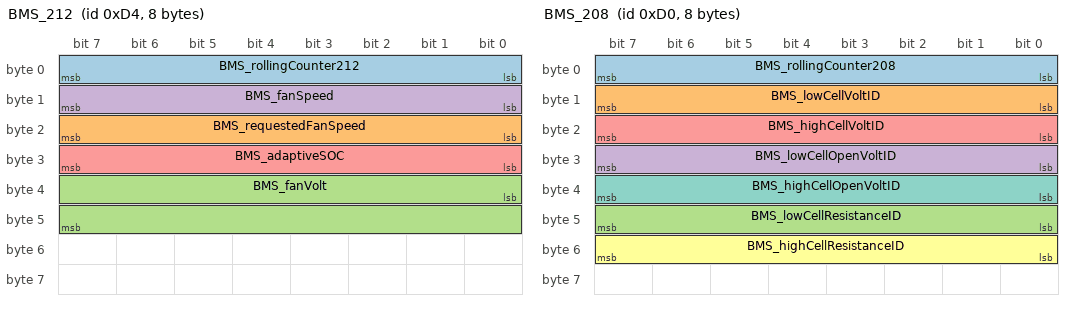
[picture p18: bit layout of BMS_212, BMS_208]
BO_ 212 BMS_212: 8 BMS
 SG_ BMS_rollingCounter212 : 0|8@1+ (1,0) [0|255] "" Vector__XXX
 SG_ BMS_requestedFanSpeed : 16|8@1+ (1,0) [0|6] "" Vector__XXX
 SG_ BMS_fanVolt : 32|16@1- (0.01,0) [-327.68|327.67] "V" Vector__XXX
 SG_ BMS_fanSpeed : 8|8@1+ (1,0) [0|6] "" Vector__XXX
 SG_ BMS_adaptiveSOC : 24|8@1- (0.5,0) [0|100] "%" Vector__XXX

BO_ 211 BMS_211: 8 BMS
 SG_ BMS_rollingCounter211 : 0|8@1+ (1,0) [0|255] "" Vector__XXX
 SG_ BMS_maxPackDCL : 16|16@1- (1,0) [-32768|32767] "A" Vector__XXX
 SG_ BMS_maxPackCCL : 32|16@1- (1,0) [-32768|32767] "A" Vector__XXX
 SG_ BMS_avgPackCurr : 48|16@1- (0.1,0) [-3276.8|3276.7] "A" Vector__XXX

BO_ 210 BMS_210: 8 BMS
 SG_ BMS_rollingCounter210 : 0|8@1+ (1,0) [0|255] "" Vector__XXX
 SG_ BMS_packOpenVolt : 48|16@1- (0.1,0) [-3276.8|3276.7] "V" Vector__XXX
 SG_ BMS_packDischargeCurrLimkW : 32|16@1- (0.1,0) [-3276.8|3276.7] "kW" Vector__XXX
 SG_ BMS_packDischargeCurrLim : 16|16@1- (1,0) [-32768|32767] "A" Vector__XXX

BO_ 209 BMS_209: 8 BMS
 SG_ BMS_totalPackADC : 48|16@1- (0.1,0) [-3276.8|3276.7] "V" Vector__XXX
 SG_ BMS_rollingCounter209 : 0|8@1+ (1,0) [0|255] "" Vector__XXX
 SG_ BMS_packChargeCurrLimkW : 32|16@1- (0.1,0) [-3276.8|3276.7] "kW" Vector__XXX
 SG_ BMS_packChargeCurrLim : 16|16@1- (1,0) [-32768|32767] "A" Vector__XXX

BO_ 208 BMS_208: 8 BMS
 SG_ BMS_rollingCounter208 : 0|8@1+ (1,0) [0|255] "" Vector__XXX
 SG_ BMS_lowCellVoltID : 8|8@1+ (1,0) [1|180] "" Vector__XXX
 SG_ BMS_lowCellResistanceID : 40|8@1+ (1,0) [1|180] "" Vector__XXX
 SG_ BMS_lowCellOpenVoltID : 24|8@1+ (1,0) [1|180] "" Vector__XXX
 SG_ BMS_highCellVoltID : 16|8@1+ (1,0) [1|180] "" Vector__XXX
 SG_ BMS_highCellResistanceID : 48|8@1+ (1,0) [1|180] "" Vector__XXX
 SG_ BMS_highCellOpenVoltID : 32|8@1+ (1,0) [1|180] "" Vector__XXX

BO_ 207 BMS_207: 8 BMS
 SG_ BMS_rollingCounter207 : 0|8@1+ (1,0) [0|255] "" Vector__XXX
 SG_ BMS_pwrInputVolt : 48|16@1- (0.1,0) [-3276.8|3276.7] "V" Vector__XXX
 SG_ BMS_minCellVolt : 32|16@1- (0.0001,0) [-3.2768|3.2767] "V" Vector__XXX
 SG_ BMS_maxCellVolt : 16|16@1- (0.0001,0) [-3.2768|3.2767] "V" Vector__XXX

BO_ 206 BMS_206: 8 BMS
 SG_ BMS_rollingCounter206 : 0|8@1+ (1,0) [0|255] "" Vector__XXX
 SG_ BMS_lowCellInternalResistance : 16|16@1- (0.01,0) [-327.68|327.67] "mOhm" Vector__XXX
 SG_ BMS_highCellInternalResistance : 32|16@1- (0.01,0) [-327.68|327.67] "mOhm" Vector__XXX
 SG_ BMS_avgCellInternalResistance : 48|16@1- (0.01,0) [-327.68|327.67] "mOhm" Vector__XXX

BO_ 205 BMS_205: 8 BMS
 SG_ BMS_rollingCounter205 : 0|8@1+ (1,0) [0|255] "" Vector__XXX
 SG_ BMS_lowCellOpenVolt : 16|16@1- (0.0001,0) [-3.2768|3.2767] "V" Vector__XXX
 SG_ BMS_highCellOpenVolt : 32|16@1- (0.0001,0) [-3.2768|3.2767] "V" Vector__XXX
 SG_ BMS_avgCellOpenVolt : 48|16@1- (0.0001,0) [-3.2768|3.2767] "V" Vector__XXX

BO_ 204 BMS_204: 8 BMS
 SG_ BMS_rollingCounter204 : 0|8@1+ (1,0) [0|255] "" Vector__XXX
 SG_ BMS_lowCellVolt : 16|16@1- (0.0001,0) [-3.2768|3.2767] "V" Vector__XXX
 SG_ BMS_highCellVolt : 32|16@1- (0.0001,0) [-3.2768|3.2767] "V" Vector__XXX
 SG_ BMS_avgCellVolt : 48|16@1- (0.0001,0) [-3.2768|3.2767] "V" Vector__XXX

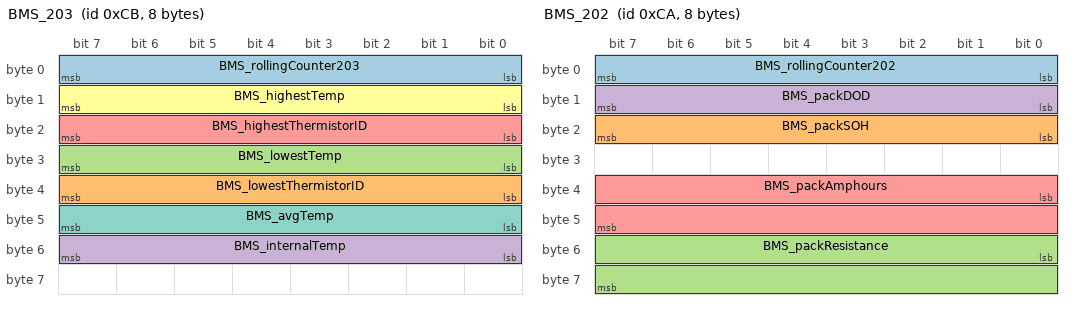
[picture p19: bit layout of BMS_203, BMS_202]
BO_ 203 BMS_203: 8 BMS
 SG_ BMS_rollingCounter203 : 0|8@1+ (1,0) [0|255] "" Vector__XXX
 SG_ BMS_lowestThermistorID : 32|8@1+ (1,0) [1|180] "" Vector__XXX
 SG_ BMS_lowestTemp : 24|8@1- (1,0) [-5|100] "degC" Vector__XXX
 SG_ BMS_internalTemp : 48|8@1- (1,0) [-5|100] "degC" Vector__XXX
 SG_ BMS_highestThermistorID : 16|8@1+ (1,0) [1|180] "" Vector__XXX
 SG_ BMS_highestTemp : 8|8@1- (1,0) [-5|100] "degC" Vector__XXX
 SG_ BMS_avgTemp : 40|8@1- (1,0) [-5|100] "degC" Vector__XXX

BO_ 202 BMS_202: 8 BMS
 SG_ BMS_rollingCounter202 : 0|8@1+ (1,0) [0|255] "" Vector__XXX
 SG_ BMS_packSOH : 16|8@1- (1,0) [0|100] "%" Vector__XXX
 SG_ BMS_packResistance : 48|16@1- (1,0) [-32768|32767] "mOhm" Vector__XXX
 SG_ BMS_packDOD : 8|8@1- (0.5,0) [0|100] "%" Vector__XXX
 SG_ BMS_packAmphours : 32|16@1- (0.1,0) [-3276.8|3276.7] "Ahr" Vector__XXX

BO_ 201 BMS_201: 8 BMS
 SG_ BMS_rollingCounter201 : 0|8@1+ (1,0) [0|255] "" Vector__XXX
 SG_ BMS_packSummedVolt : 16|16@1- (0.01,0) [-327.68|327.67] "V" Vector__XXX
 SG_ BMS_minPackVolt : 48|16@1- (0.1,0) [-3276.8|3276.7] "V" Vector__XXX
 SG_ BMS_maxPackVolt : 32|16@1- (0.1,0) [-3276.8|3276.7] "V" Vector__XXX

BO_ 200 BMS_200: 8 BMS
 SG_ BMS_rollingCounter200 : 0|8@1+ (1,0) [0|255] "" Vector__XXX
 SG_ BMS_packVolt : 32|16@1- (0.1,0) [-3276.8|3276.7] "V" Vector__XXX
 SG_ BMS_packSOC : 48|8@1- (0.5,0) [0|100] "%" Vector__XXX
 SG_ BMS_packCurr : 16|16@1- (0.1,0) [-3276.8|3276.7] "A" Vector__XXX

BO_ 150 VCU_150: 8 VCU
 SG_ VCU_throttlePosition2 : 48|16@1- (0.1,0) [0|100] "%" Vector__XXX
 SG_ VCU_throttlePosition1 : 32|16@1- (0.1,0) [0|100] "%" Vector__XXX
 SG_ VCU_throttlePosition : 16|16@1- (0.1,0) [0|100] "%" Vector__XXX
 SG_ VCU_counterMsg150 : 0|4@1+ (1,0) [0|15] "" Vector__XXX

CM_ SG_ 554 RAND_rateZHor "Z-axis rate in horizontal coordinate system";
CM_ SG_ 554 RAND_rateYHor "Y-axis rate in horizontal coordinate system";
CM_ SG_ 554 RAND_rateXHor "X-axis rate in horizontal coordinate system";
CM_ SG_ 553 RAND_accZHor "Z-axis acceleration in horizontal coordinate system";
CM_ SG_ 553 RAND_accYHor "Y-axis acceleration in horizontal coordinate system";
CM_ SG_ 553 RAND_accXHor "X-axis acceleration in horizontal coordinate system";
CM_ SG_ 552 RAND_pitch "Pitch angle";
CM_ SG_ 552 RAND_roll "Roll angle";
CM_ SG_ 551 RAND_accCPoi "Centripetal acceleration at point of interest";
CM_ SG_ 551 RAND_radiusPoi "Radius of curvature at point of interest";
CM_ SG_ 551 RAND_distAPoi "Cumulative distance via acceleration and speed (with point of interest compensation)";
CM_ SG_ 550 RAND_angSPoi "Slip angle at point of interest";
CM_ SG_ 550 RAND_velAPoi "Velocity via acceleration at point of interest";
CM_ SG_ 550 RAND_velYPoi "Y-axis velocity at point of interest";
CM_ SG_ 550 RAND_velXPoi "X-axis velocity at point of interest";
CM_ SG_ 501 RAND_postRadPres "Post-radiator pressure";
CM_ SG_ 501 RAND_postRadTemp "Post-radiator temperature";
CM_ SG_ 501 RAND_counterMsg501 "Counter Message 501";
CM_ SG_ 500 RAND_preRadPres "Pre-radiator pressure";
CM_ SG_ 500 RAND_preRadTemp "Pre-radiator temperature";
CM_ SG_ 500 RAND_counterMsg500 "Counter Message 500";
CM_ SG_ 162 VCU_az "Estimated vertical acceleration at CG";
CM_ SG_ 162 VCU_ay "Estimated lateral acceleration at CG";
CM_ SG_ 162 VCU_ax "Estimated longitudinal acceleration at CG";
CM_ SG_ 162 VCU_counterMsg162 "Counter Message 162";
CM_ SG_ 161 VCU_flowRateMotorOut "Motor out flow rate";
CM_ SG_ 161 VCU_flowRateMotorIn "Motor in flow rate";
CM_ SG_ 161 VCU_flowRateInverterOut "Inverter out flow rate";
CM_ SG_ 161 VCU_counterMsg161 "Counter Message 161";
CM_ SG_ 363 STMM_segmentVolt811 "Segment 8 module 11";
CM_ SG_ 363 STMM_segmentVolt810 "Segment 8 module 10";
CM_ SG_ 363 STMM_segmentVolt809 "Segment 8 module 9";
CM_ SG_ 363 STMM_counterMsg363 "Counter Message 363";
CM_ SG_ 362 STMM_segmentVolt808 "Segment 8 module 8";
CM_ SG_ 362 STMM_segmentVolt807 "Segment 8 module 7";
CM_ SG_ 362 STMM_segmentVolt806 "Segment 8 module 6";
CM_ SG_ 362 STMM_counterMsg362 "Counter Message 362";
CM_ SG_ 361 STMM_segmentVolt805 "Segment 8 module 5";
CM_ SG_ 361 STMM_segmentVolt804 "Segment 8 module 4";
CM_ SG_ 361 STMM_segmentVolt803 "Segment 8 module 3";
CM_ SG_ 361 STMM_counterMsg361 "Counter Message 361";
CM_ SG_ 360 STMM_segmentVolt802 "Segment 8 module 2";
CM_ SG_ 360 STMM_segmentVolt801 "Segment 8 module 1";
CM_ SG_ 360 STMM_segmentVolt800 "Segment 8 module 0";
CM_ SG_ 360 STMM_counterMsg360 "Counter Message 360";
CM_ SG_ 359 STMM_segmentVolt711 "Segment 7 module 11";
CM_ SG_ 359 STMM_segmentVolt710 "Segment 7 module 10";
CM_ SG_ 359 STMM_segmentVolt709 "Segment 7 module 9";
CM_ SG_ 359 STMM_counterMsg359 "Counter Message 359";
CM_ SG_ 358 STMM_segmentVolt708 "Segment 7 module 8";
CM_ SG_ 358 STMM_segmentVolt707 "Segment 7 module 7";
CM_ SG_ 358 STMM_segmentVolt706 "Segment 7 module 6";
CM_ SG_ 358 STMM_counterMsg358 "Counter Message 358";
CM_ SG_ 357 STMM_segmentVolt705 "Segment 7 module 5";
CM_ SG_ 357 STMM_segmentVolt704 "Segment 7 module 4";
CM_ SG_ 357 STMM_segmentVolt703 "Segment 7 module 3";
CM_ SG_ 357 STMM_counterMsg357 "Counter Message 357";
CM_ SG_ 356 STMM_segmentVolt702 "Segment 7 module 2";
CM_ SG_ 356 STMM_segmentVolt701 "Segment 7 module 1";
CM_ SG_ 356 STMM_segmentVolt700 "Segment 7 module 0";
CM_ SG_ 356 STMM_counterMsg356 "Counter Message 356";
CM_ SG_ 355 STMM_segmentVolt611 "Segment 6 module 11";
CM_ SG_ 355 STMM_segmentVolt610 "Segment 6 module 10";
CM_ SG_ 355 STMM_segmentVolt609 "Segment 6 module 9";
CM_ SG_ 355 STMM_counterMsg355 "Counter Message 355";
CM_ SG_ 354 STMM_segmentVolt608 "Segment 6 module 8";
CM_ SG_ 354 STMM_segmentVolt607 "Segment 6 module 7";
CM_ SG_ 354 STMM_segmentVolt606 "Segment 6 module 6";
CM_ SG_ 354 STMM_counterMsg354 "Counter Message 354";
CM_ SG_ 353 STMM_segmentVolt605 "Segment 6 module 5";
CM_ SG_ 353 STMM_segmentVolt604 "Segment 6 module 4";
CM_ SG_ 353 STMM_segmentVolt603 "Segment 6 module 3";
CM_ SG_ 353 STMM_counterMsg353 "Counter Message 353";
CM_ SG_ 352 STMM_segmentVolt602 "Segment 6 module 2";
CM_ SG_ 352 STMM_segmentVolt601 "Segment 6 module 1";
CM_ SG_ 352 STMM_segmentVolt600 "Segment 6 module 0";
CM_ SG_ 352 STMM_counterMsg352 "Counter Message 352";
CM_ SG_ 351 STMM_segmentVolt511 "Segment 5 module 11";
CM_ SG_ 351 STMM_segmentVolt510 "Segment 5 module 10";
CM_ SG_ 351 STMM_segmentVolt509 "Segment 5 module 9";
CM_ SG_ 351 STMM_counterMsg351 "Counter Message 351";
CM_ SG_ 350 STMM_segmentVolt508 "Segment 5 module 8";
CM_ SG_ 350 STMM_segmentVolt507 "Segment 5 module 7";
CM_ SG_ 350 STMM_segmentVolt506 "Segment 5 module 6";
CM_ SG_ 350 STMM_counterMsg350 "Counter Message 350";
CM_ SG_ 349 STMM_segmentVolt505 "Segment 5 module 5";
CM_ SG_ 349 STMM_segmentVolt504 "Segment 5 module 4";
CM_ SG_ 349 STMM_segmentVolt503 "Segment 5 module 3";
CM_ SG_ 349 STMM_counterMsg349 "Counter Message 349";
CM_ SG_ 348 STMM_segmentVolt502 "Segment 5 module 2";
CM_ SG_ 348 STMM_segmentVolt501 "Segment 5 module 1";
CM_ SG_ 348 STMM_segmentVolt500 "Segment 5 module 0";
CM_ SG_ 348 STMM_counterMsg348 "Counter Message 348";
CM_ SG_ 347 STMM_segmentVolt411 "Segment 4 module 11";
CM_ SG_ 347 STMM_segmentVolt410 "Segment 4 module 10";
CM_ SG_ 347 STMM_segmentVolt409 "Segment 4 module 9";
CM_ SG_ 347 STMM_counterMsg347 "Counter Message 347";
CM_ SG_ 346 STMM_segmentVolt408 "Segment 4 module 8";
CM_ SG_ 346 STMM_segmentVolt407 "Segment 4 module 7";
CM_ SG_ 346 STMM_segmentVolt406 "Segment 4 module 6";
CM_ SG_ 346 STMM_counterMsg346 "Counter Message 346";
CM_ SG_ 345 STMM_segmentVolt405 "Segment 4 module 5";
CM_ SG_ 345 STMM_segmentVolt404 "Segment 4 module 4";
CM_ SG_ 345 STMM_segmentVolt403 "Segment 4 module 3";
CM_ SG_ 345 STMM_counterMsg345 "Counter Message 345";
CM_ SG_ 344 STMM_segmentVolt402 "Segment 4 module 2";
CM_ SG_ 344 STMM_segmentVolt401 "Segment 4 module 1";
CM_ SG_ 344 STMM_segmentVolt400 "Segment 4 module 0";
CM_ SG_ 344 STMM_counterMsg344 "Counter Message 344";
CM_ SG_ 343 STMM_segmentVolt311 "Segment 3 module 11";
CM_ SG_ 343 STMM_segmentVolt310 "Segment 3 module 10";
CM_ SG_ 343 STMM_segmentVolt309 "Segment 3 module 9";
CM_ SG_ 343 STMM_counterMsg343 "Counter Message 343";
CM_ SG_ 342 STMM_segmentVolt308 "Segment 3 module 8";
CM_ SG_ 342 STMM_segmentVolt307 "Segment 3 module 7";
CM_ SG_ 342 STMM_segmentVolt306 "Segment 3 module 6";
CM_ SG_ 342 STMM_counterMsg342 "Counter Message 342";
CM_ SG_ 341 STMM_segmentVolt305 "Segment 3 module 5";
CM_ SG_ 341 STMM_segmentVolt304 "Segment 3 module 4";
CM_ SG_ 341 STMM_segmentVolt303 "Segment 3 module 3";
CM_ SG_ 341 STMM_counterMsg341 "Counter Message 341";
CM_ SG_ 340 STMM_segmentVolt302 "Segment 3 module 2";
CM_ SG_ 340 STMM_segmentVolt301 "Segment 3 module 1";
CM_ SG_ 340 STMM_segmentVolt300 "Segment 3 module 0";
CM_ SG_ 340 STMM_counterMsg340 "Counter Message 340";
CM_ SG_ 339 STMM_segmentVolt211 "Segment 2 module 11";
CM_ SG_ 339 STMM_segmentVolt210 "Segment 2 module 10";
CM_ SG_ 339 STMM_segmentVolt209 "Segment 2 module 9";
CM_ SG_ 339 STMM_counterMsg339 "Counter Message 339";
CM_ SG_ 338 STMM_segmentVolt208 "Segment 2 module 8";
CM_ SG_ 338 STMM_segmentVolt207 "Segment 2 module 7";
CM_ SG_ 338 STMM_segmentVolt206 "Segment 2 module 6";
CM_ SG_ 338 STMM_counterMsg338 "Counter Message 338";
CM_ SG_ 337 STMM_segmentVolt205 "Segment 2 module 5";
CM_ SG_ 337 STMM_segmentVolt204 "Segment 2 module 4";
CM_ SG_ 337 STMM_segmentVolt203 "Segment 2 module 3";
CM_ SG_ 337 STMM_counterMsg337 "Counter Message 337";
CM_ SG_ 336 STMM_segmentVolt202 "Segment 2 module 2";
CM_ SG_ 336 STMM_segmentVolt201 "Segment 2 module 1";
CM_ SG_ 336 STMM_segmentVolt200 "Segment 2 module 0";
CM_ SG_ 336 STMM_counterMsg336 "Counter Message 336";
CM_ SG_ 335 STMM_segmentVolt111 "Segment 1 module 11";
CM_ SG_ 335 STMM_segmentVolt110 "Segment 1 module 10";
CM_ SG_ 335 STMM_segmentVolt109 "Segment 1 module 9";
CM_ SG_ 335 STMM_counterMsg335 "Counter Message 335";
CM_ SG_ 334 STMM_segmentVolt108 "Segment 1 module 8";
CM_ SG_ 334 STMM_segmentVolt107 "Segment 1 module 7";
CM_ SG_ 334 STMM_segmentVolt106 "Segment 1 module 6";
CM_ SG_ 334 STMM_counterMsg334 "Counter Message 334";
CM_ SG_ 333 STMM_segmentVolt105 "Segment 1 module 5";
CM_ SG_ 333 STMM_segmentVolt104 "Segment 1 module 4";
CM_ SG_ 333 STMM_segmentVolt103 "Segment 1 module 3";
CM_ SG_ 333 STMM_counterMsg333 "Counter Message 333";
CM_ SG_ 332 STMM_segmentVolt102 "Segment 1 module 2";
CM_ SG_ 332 STMM_segmentVolt101 "Segment 1 module 1";
CM_ SG_ 332 STMM_segmentVolt100 "Segment 1 module 0";
CM_ SG_ 332 STMM_counterMsg332 "Counter Message 332";
CM_ SG_ 299 STMM_counterMsg299 "Counter Message 299";
CM_ SG_ 299 STMM_segmentSync "Segment sync trigger";
CM_ SG_ 160 VCU_driveSpeed "Drive axle speed";
CM_ SG_ 160 VCU_counterMsg160 "Counter Message 160";
CM_ SG_ 159 VCU_tireTempRRO "RRO tire temperature";
CM_ SG_ 159 VCU_tireTempRRM "RRM tire temperature";
CM_ SG_ 159 VCU_tireTempRRI "RRI tire temperature";
CM_ SG_ 159 VCU_counterMsg159 "Counter Message 159";
CM_ SG_ 158 VCU_tireTempRLO "RLO tire temperature";
CM_ SG_ 158 VCU_tireTempRLM "RLM tire temperature";
CM_ SG_ 158 VCU_tireTempRLI "RLI tire temperature";
CM_ SG_ 158 VCU_counterMsg158 "Counter Message 158";
CM_ SG_ 157 VCU_tireTempFRO "FRO tire temperature";
CM_ SG_ 157 VCU_tireTempFRM "FRM tire temperature";
CM_ SG_ 157 VCU_tireTempFRI "FRI tire temperature";
CM_ SG_ 157 VCU_counterMsg157 "Counter Message 157";
CM_ SG_ 156 VCU_tireTempFLO "FLO tire temperature";
CM_ SG_ 156 VCU_tireTempFLM "FLM tire temperature";
CM_ SG_ 156 VCU_tireTempFLI "FLI tire temperature";
CM_ SG_ 156 VCU_counterMsg156 "Counter Message 156";
CM_ SG_ 155 VCU_rotorTempRR "RR rotor temperature";
CM_ SG_ 155 VCU_rotorTempRL "RL rotor temperature";
CM_ SG_ 155 VCU_counterMsg155 "Counter Message 155";
CM_ SG_ 154 VCU_rotorTempFR "FR rotor temperature";
CM_ SG_ 154 VCU_rotorTempFL "FL rotor temperature";
CM_ SG_ 154 VCU_counterMsg154 "Counter Message 154";
CM_ SG_ 2553934727 STMM_seg8Checksum "Checksum (sum of all bytes + 0x39 + length)
";
CM_ SG_ 2553934727 STMM_seg8ThermIDLow "The ID of the thermistor with the lowest value
";
CM_ SG_ 2553934727 STMM_seg8ThermIDHigh "The ID of the thermistor with the highest value
";
CM_ SG_ 2553934727 STMM_seg8ThermsEnabled "Number of thermistors enabled
";
CM_ SG_ 2553934727 STMM_seg8ThermValAvg "Average thermistor value
";
CM_ SG_ 2553934727 STMM_seg8ThermValHigh "Highest thermistor value
";
CM_ SG_ 2553934727 STMM_seg8ThermValLow "Lowest thermistor value
";
CM_ SG_ 2553934727 STMM_seg8ThermModNum "Thermistor module number
";
CM_ SG_ 2553934726 STMM_seg7Checksum "Checksum (sum of all bytes + 0x39 + length)
";
CM_ SG_ 2553934726 STMM_seg7ThermIDLow "The ID of the thermistor with the lowest value
";
CM_ SG_ 2553934726 STMM_seg7ThermIDHigh "The ID of the thermistor with the highest value
";
CM_ SG_ 2553934726 STMM_seg7ThermsEnabled "Number of thermistors enabled
";
CM_ SG_ 2553934726 STMM_seg7ThermValAvg "Average thermistor value
";
CM_ SG_ 2553934726 STMM_seg7ThermValHigh "Highest thermistor value
";
CM_ SG_ 2553934726 STMM_seg7ThermValLow "Lowest thermistor value
";
CM_ SG_ 2553934726 STMM_seg7ThermModNum "Thermistor module number
";
CM_ SG_ 2553934725 STMM_seg6Checksum "Checksum (sum of all bytes + 0x39 + length)
";
CM_ SG_ 2553934725 STMM_seg6ThermIDLow "The ID of the thermistor with the lowest value
";
CM_ SG_ 2553934725 STMM_seg6ThermIDHigh "The ID of the thermistor with the highest value
";
CM_ SG_ 2553934725 STMM_seg6ThermsEnabled "Number of thermistors enabled
";
CM_ SG_ 2553934725 STMM_seg6ThermValAvg "Average thermistor value
";
CM_ SG_ 2553934725 STMM_seg6ThermValHigh "Highest thermistor value
";
CM_ SG_ 2553934725 STMM_seg6ThermValLow "Lowest thermistor value
";
CM_ SG_ 2553934725 STMM_seg6ThermModNum "Thermistor module number
";
CM_ SG_ 2553934724 STMM_seg5Checksum "Checksum (sum of all bytes + 0x39 + length)
";
CM_ SG_ 2553934724 STMM_seg5ThermIDLow "The ID of the thermistor with the lowest value
";
CM_ SG_ 2553934724 STMM_seg5ThermIDHigh "The ID of the thermistor with the highest value
";
CM_ SG_ 2553934724 STMM_seg5ThermsEnabled "Number of thermistors enabled
";
CM_ SG_ 2553934724 STMM_seg5ThermValAvg "Average thermistor value
";
CM_ SG_ 2553934724 STMM_seg5ThermValHigh "Highest thermistor value
";
CM_ SG_ 2553934724 STMM_seg5ThermValLow "Lowest thermistor value
";
CM_ SG_ 2553934724 STMM_seg5ThermModNum "Thermistor module number
";
CM_ SG_ 2553934723 STMM_seg4Checksum "Checksum (sum of all bytes + 0x39 + length)
";
CM_ SG_ 2553934723 STMM_seg4ThermIDLow "The ID of the thermistor with the lowest value
";
CM_ SG_ 2553934723 STMM_seg4ThermIDHigh "The ID of the thermistor with the highest value
";
CM_ SG_ 2553934723 STMM_seg4ThermsEnabled "Number of thermistors enabled
";
CM_ SG_ 2553934723 STMM_seg4ThermValAvg "Average thermistor value
";
CM_ SG_ 2553934723 STMM_seg4ThermValHigh "Highest thermistor value
";
CM_ SG_ 2553934723 STMM_seg4ThermValLow "Lowest thermistor value
";
CM_ SG_ 2553934723 STMM_seg4ThermModNum "Thermistor module number
";
CM_ SG_ 2553934722 STMM_seg3Checksum "Checksum (sum of all bytes + 0x39 + length)
";
CM_ SG_ 2553934722 STMM_seg3ThermIDLow "The ID of the thermistor with the lowest value
";
CM_ SG_ 2553934722 STMM_seg3ThermIDHigh "The ID of the thermistor with the highest value
";
CM_ SG_ 2553934722 STMM_seg3ThermsEnabled "Number of thermistors enabled
";
CM_ SG_ 2553934722 STMM_seg3ThermValAvg "Average thermistor value
";
CM_ SG_ 2553934722 STMM_seg3ThermValHigh "Highest thermistor value
";
CM_ SG_ 2553934722 STMM_seg3ThermValLow "Lowest thermistor value
";
CM_ SG_ 2553934722 STMM_seg3ThermModNum "Thermistor module number
";
CM_ SG_ 2553934721 STMM_seg2Checksum "Checksum (sum of all bytes + 0x39 + length)
";
CM_ SG_ 2553934721 STMM_seg2ThermIDLow "The ID of the thermistor with the lowest value
";
CM_ SG_ 2553934721 STMM_seg2ThermIDHigh "The ID of the thermistor with the highest value
";
CM_ SG_ 2553934721 STMM_seg2ThermsEnabled "Number of thermistors enabled
";
CM_ SG_ 2553934721 STMM_seg2ThermValAvg "Average thermistor value
";
CM_ SG_ 2553934721 STMM_seg2ThermValHigh "Highest thermistor value
";
CM_ SG_ 2553934721 STMM_seg2ThermValLow "Lowest thermistor value
";
CM_ SG_ 2553934721 STMM_seg2ThermModNum "Thermistor module number
";
CM_ SG_ 2553934720 STMM_seg1Checksum "Checksum (sum of all bytes + 0x39 + length)
";
CM_ SG_ 2553934720 STMM_seg1ThermIDLow "The ID of the thermistor with the lowest value
";
CM_ SG_ 2553934720 STMM_seg1ThermIDHigh "The ID of the thermistor with the highest value
";
CM_ SG_ 2553934720 STMM_seg1ThermsEnabled "Number of thermistors enabled
";
CM_ SG_ 2553934720 STMM_seg1ThermValAvg "Average thermistor value
";
CM_ SG_ 2553934720 STMM_seg1ThermValHigh "Highest thermistor value
";
CM_ SG_ 2553934720 STMM_seg1ThermValLow "Lowest thermistor value
";
CM_ SG_ 2553934720 STMM_seg1ThermModNum "Thermistor module number
";
CM_ SG_ 153 VCU_coolSwitch "Cool switch signal";
CM_ SG_ 153 VCU_pwrDownSwitch "Power down switch signal";
CM_ SG_ 153 VCU_pwrUpSwitch "Power up switch signal";
CM_ SG_ 153 VCU_startSwitch "Start switch signal";
CM_ SG_ 153 VCU_counterMsg153 "Counter Message 153";
CM_ SG_ 152 VCU_ShifterState "Torque-Shifter State";
CM_ SG_ 152 VCU_rtmSound "Ready To Move sound";
CM_ SG_ 152 VCU_mainMinusContactorState "Main- contactor state";
CM_ SG_ 152 VCU_mainPlusContactorState "Main+ contactor state";
CM_ SG_ 152 VCU_prechargeContactorState "Precharge contactor state";
CM_ SG_ 152 VCU_dischargeContactorState "Discharge contactor state";
CM_ SG_ 152 VCU_vehicleState "Vehicle state";
CM_ SG_ 152 VCU_counterMsg152 "Counter Message 152";
CM_ SG_ 151 VCU_brakePressureR "Rear brake pressure sensor";
CM_ SG_ 151 VCU_brakePressureF "Front brake pressure sensor";
CM_ SG_ 151 VCU_brakeBias "Brake bias";
CM_ SG_ 151 VCU_counterMsg151 "Counter Message 151";
CM_ SG_ 380 MM5_az "Acceleration Z Axis
";
CM_ SG_ 376 MM5_rollRate "Roll Rate
";
CM_ SG_ 376 MM5_ax "Acceleration X Axis
";
CM_ SG_ 372 MM5_yawRate "Yaw Rate
";
CM_ SG_ 372 MM5_ay "Acceleration Y Axis
";
CM_ SG_ 331 STMM_segmentTemp811 "Segment 8 module 11
";
CM_ SG_ 331 STMM_segmentTemp810 "Segment 8 module 10
";
CM_ SG_ 331 STMM_segmentTemp809 "Segment 8 module 9
";
CM_ SG_ 331 STMM_counterMsg331 "Counter Message 331
";
CM_ SG_ 330 STMM_segmentTemp808 "Segment 8 module 8
";
CM_ SG_ 330 STMM_segmentTemp807 "Segment 8 module 7
";
CM_ SG_ 330 STMM_segmentTemp806 "Segment 8 module 6
";
CM_ SG_ 330 STMM_counterMsg330 "Counter Message 330
";
CM_ SG_ 329 STMM_segmentTemp805 "Segment 8 module 5
";
CM_ SG_ 329 STMM_segmentTemp804 "Segment 8 module 4
";
CM_ SG_ 329 STMM_segmentTemp803 "Segment 8 module 3
";
CM_ SG_ 329 STMM_counterMsg329 "Counter Message 329
";
CM_ SG_ 328 STMM_segmentTemp802 "Segment 8 module 2
";
CM_ SG_ 328 STMM_segmentTemp801 "Segment 8 module 1
";
CM_ SG_ 328 STMM_segmentTemp800 "Segment 8 module 0
";
CM_ SG_ 328 STMM_counterMsg328 "Counter Message 328
";
CM_ SG_ 327 STMM_segmentTemp711 "Segment 7 module 11
";
CM_ SG_ 327 STMM_segmentTemp710 "Segment 7 module 10
";
CM_ SG_ 327 STMM_segmentTemp709 "Segment 7 module 9
";
CM_ SG_ 327 STMM_counterMsg327 "Counter Message 327
";
CM_ SG_ 326 STMM_segmentTemp708 "Segment 7 module 8
";
CM_ SG_ 326 STMM_segmentTemp707 "Segment 7 module 7
";
CM_ SG_ 326 STMM_segmentTemp706 "Segment 7 module 6
";
CM_ SG_ 326 STMM_counterMsg326 "Counter Message 326
";
CM_ SG_ 325 STMM_segmentTemp705 "Segment 7 module 5
";
CM_ SG_ 325 STMM_segmentTemp704 "Segment 7 module 4
";
CM_ SG_ 325 STMM_segmentTemp703 "Segment 7 module 3
";
CM_ SG_ 325 STMM_counterMsg325 "Counter Message 325
";
CM_ SG_ 324 STMM_segmentTemp701 "Segment 7 module 1
";
CM_ SG_ 324 STMM_segmentTemp700 "Segment 7 module 0
";
CM_ SG_ 324 STMM_counterMsg324 "Counter Message 324
";
CM_ SG_ 323 STMM_segmentTemp611 "Segment 6 module 11
";
CM_ SG_ 323 STMM_segmentTemp610 "Segment 6 module 10
";
CM_ SG_ 323 STMM_segmentTemp609 "Segment 6 module 9
";
CM_ SG_ 323 STMM_counterMsg323 "Counter Message 323
";
CM_ SG_ 322 STMM_segmentTemp608 "Segment 6 module 8
";
CM_ SG_ 322 STMM_segmentTemp607 "Segment 6 module 7
";
CM_ SG_ 322 STMM_segmentTemp606 "Segment 6 module 6
";
CM_ SG_ 322 STMM_counterMsg322 "Counter Message 322
";
CM_ SG_ 321 STMM_segmentTemp605 "Segment 6 module 5
";
CM_ SG_ 321 STMM_segmentTemp604 "Segment 6 module 4
";
CM_ SG_ 321 STMM_segmentTemp603 "Segment 6 module 3
";
CM_ SG_ 321 STMM_counterMsg321 "Counter Message 321
";
CM_ SG_ 320 STMM_segmentTemp602 "Segment 6 module 2
";
CM_ SG_ 320 STMM_segmentTemp601 "Segment 6 module 1
";
CM_ SG_ 320 STMM_segmentTemp600 "Segment 6 module 0
";
CM_ SG_ 320 STMM_counterMsg320 "Counter Message 320
";
CM_ SG_ 319 STMM_segmentTemp511 "Segment 5 module 11
";
CM_ SG_ 319 STMM_segmentTemp510 "Segment 5 module 10
";
CM_ SG_ 319 STMM_segmentTemp509 "Segment 5 module 9
";
CM_ SG_ 319 STMM_counterMsg319 "Counter Message 319
";
CM_ SG_ 318 STMM_segmentTemp508 "Segment 5 module 8
";
CM_ SG_ 318 STMM_segmentTemp507 "Segment 5 module 7
";
CM_ SG_ 318 STMM_segmentTemp506 "Segment 5 module 6
";
CM_ SG_ 318 STMM_counterMsg318 "Counter Message 318
";
CM_ SG_ 317 STMM_segmentTemp505 "Segment 5 module 5
";
CM_ SG_ 317 STMM_segmentTemp504 "Segment 5 module 4
";
CM_ SG_ 317 STMM_segmentTemp503 "Segment 5 module 3
";
CM_ SG_ 317 STMM_counterMsg317 "Counter Message 317
";
CM_ SG_ 316 STMM_segmentTemp502 "Segment 5 module 2
";
CM_ SG_ 316 STMM_segmentTemp501 "Segment 5 module 1
";
CM_ SG_ 316 STMM_segmentTemp500 "Segment 5 module 0
";
CM_ SG_ 316 STMM_counterMsg316 "Counter Message 316
";
CM_ SG_ 315 STMM_segmentTemp411 "Segment 4 module 11
";
CM_ SG_ 315 STMM_segmentTemp410 "Segment 4 module 10
";
CM_ SG_ 315 STMM_segmentTemp409 "Segment 4 module 9
";
CM_ SG_ 315 STMM_counterMsg315 "Counter Message 315
";
CM_ SG_ 314 STMM_segmentTemp408 "Segment 4 module 8
";
CM_ SG_ 314 STMM_segmentTemp407 "Segment 4 module 7
";
CM_ SG_ 314 STMM_segmentTemp406 "Segment 4 module 6
";
CM_ SG_ 314 STMM_counterMsg314 "Counter Message 314
";
CM_ SG_ 313 STMM_segmentTemp405 "Segment 4 module 5
";
CM_ SG_ 313 STMM_segmentTemp404 "Segment 4 module 4
";
CM_ SG_ 313 STMM_segmentTemp403 "Segment 4 module 3
";
CM_ SG_ 313 STMM_counterMsg313 "Counter Message 313
";
CM_ SG_ 312 STMM_segmentTemp402 "Segment 4 module 2
";
CM_ SG_ 312 STMM_segmentTemp401 "Segment 4 module 1
";
CM_ SG_ 312 STMM_segmentTemp400 "Segment 4 module 0
";
CM_ SG_ 312 STMM_counterMsg312 "Counter Message 312
";
CM_ SG_ 311 STMM_segmentTemp311 "Segment 3 module 11
";
CM_ SG_ 311 STMM_segmentTemp310 "Segment 3 module 10
";
CM_ SG_ 311 STMM_segmentTemp309 "Segment 3 module 9
";
CM_ SG_ 311 STMM_counterMsg311 "Counter Message 311
";
CM_ SG_ 310 STMM_segmentTemp308 "Segment 3 module 8
";
CM_ SG_ 310 STMM_segmentTemp307 "Segment 3 module 7
";
CM_ SG_ 310 STMM_segmentTemp306 "Segment 3 module 6
";
CM_ SG_ 310 STMM_counterMsg310 "Counter Message 310
";
CM_ SG_ 309 STMM_segmentTemp305 "Segment 3 module 5
";
CM_ SG_ 309 STMM_segmentTemp304 "Segment 3 module 4
";
CM_ SG_ 309 STMM_segmentTemp303 "Segment 3 module 3
";
CM_ SG_ 309 STMM_counterMsg309 "Counter Message 309
";
CM_ SG_ 308 STMM_segmentTemp302 "Segment 3 module 2
";
CM_ SG_ 308 STMM_segmentTemp301 "Segment 3 module 1
";
CM_ SG_ 308 STMM_segmentTemp300 "Segment 3 module 0
";
CM_ SG_ 308 STMM_counterMsg308 "Counter Message 308
";
CM_ SG_ 307 STMM_segmentTemp211 "Segment 2 module 11
";
CM_ SG_ 307 STMM_segmentTemp210 "Segment 2 module 10
";
CM_ SG_ 307 STMM_segmentTemp209 "Segment 2 module 9
";
CM_ SG_ 307 STMM_counterMsg307 "Counter Message 307
";
CM_ SG_ 306 STMM_segmentTemp208 "Segment 2 module 8
";
CM_ SG_ 306 STMM_segmentTemp207 "Segment 2 module 7
";
CM_ SG_ 306 STMM_segmentTemp206 "Segment 2 module 6
";
CM_ SG_ 306 STMM_counterMsg306 "Counter Message 306
";
CM_ SG_ 305 STMM_segmentTemp205 "Segment 2 module 5
";
CM_ SG_ 305 STMM_segmentTemp204 "Segment 2 module 4
";
CM_ SG_ 305 STMM_segmentTemp203 "Segment 2 module 3
";
CM_ SG_ 305 STMM_counterMsg305 "Counter Message 305
";
CM_ SG_ 304 STMM_segmentTemp202 "Segment 2 module 2
";
CM_ SG_ 304 STMM_segmentTemp201 "Segment 2 module 1
";
CM_ SG_ 304 STMM_segmentTemp200 "Segment 2 module 0
";
CM_ SG_ 304 STMM_counterMsg304 "Counter Message 304
";
CM_ SG_ 303 STMM_segmentTemp111 "Segment 1 module 11
";
CM_ SG_ 303 STMM_segmentTemp110 "Segment 1 module 10
";
CM_ SG_ 303 STMM_segmentTemp109 "Segment 1 module 9
";
CM_ SG_ 303 STMM_counterMsg303 "Counter Message 303
";
CM_ SG_ 302 STMM_segmentTemp108 "Segment 1 module 8
";
CM_ SG_ 302 STMM_segmentTemp107 "Segment 1 module 7
";
CM_ SG_ 302 STMM_segmentTemp106 "Segment 1 module 6
";
CM_ SG_ 302 STMM_counterMsg302 "Counter Message 302
";
CM_ SG_ 301 STMM_segmentTemp105 "Segment 1 module 5
";
CM_ SG_ 301 STMM_segmentTemp104 "Segment 1 module 4
";
CM_ SG_ 301 STMM_segmentTemp103 "Segment 1 module 3
";
CM_ SG_ 301 STMM_counterMsg301 "Counter Message 301
";
CM_ SG_ 300 STMM_segmentTemp102 "Segment 1 module 2
";
CM_ SG_ 300 STMM_segmentTemp101 "Segment 1 module 1
";
CM_ SG_ 300 STMM_segmentTemp100 "Segment 1 module 0
";
CM_ SG_ 300 STMM_counterMsg300 "Counter Message 300
";
CM_ SG_ 250 DD_teensyTemp "Teensy Board Temp
";
CM_ SG_ 250 DD_counterMsg250 "Counter Message 250";
CM_ SG_ 250 DD_boardTemp "Board Temp
";
CM_ SG_ 414 PDM_runtimeMinutes "Runtime Minutes
";
CM_ SG_ 414 PDM_runtimeHours "Runtime Hours
";
CM_ SG_ 414 PDM_counterMsg414 "Counter Message 414
";
CM_ SG_ 414 PDM_carMiles "Car Miles
";
CM_ SG_ 413 PDM_keepAliveVoltMin "Keep Alive Minimum Voltage
";
CM_ SG_ 413 PDM_keepAliveVoltMax "Keep Alive Maximum Voltage
";
CM_ SG_ 413 PDM_keepAliveVoltAvg "Keep Alive Average Voltage
";
CM_ SG_ 413 PDM_counterMsg413 "Counter Message 413
";
CM_ SG_ 412 PDM_dataVoltMin "Data Minimum Voltage
";
CM_ SG_ 412 PDM_dataVoltMax "Data Maximum Voltage
";
CM_ SG_ 412 PDM_dataVoltAvg "Data Average Voltage
";
CM_ SG_ 412 PDM_counterMsg412 "Counter Message 412
";
CM_ SG_ 411 PDM_glvVoltMin "GLV Minimum Voltage
";
CM_ SG_ 411 PDM_glvVoltMax "GLV Maximum Voltage
";
CM_ SG_ 411 PDM_glvVoltAvg "GLV Average Voltage
";
CM_ SG_ 411 PDM_counterMsg411 "Counter Message 411
";
CM_ SG_ 410 PDM_uptime "PDM Teensy Uptime
";
CM_ SG_ 409 PDM_teensyTemp "Teensy Board Temperature
";
CM_ SG_ 409 PDM_wpDutyCycle "Water Pump Duty Cycle
";
CM_ SG_ 409 PDM_fanRightDutyCycle "Right Fan Duty Cycle
";
CM_ SG_ 409 PDM_fanLeftDutyCycle "Left Fan Duty Cycle
";
CM_ SG_ 409 PDM_counterMsg409 "Counter Message 409
";
CM_ SG_ 408 PDM_wpVoltMin "Water Pump Minimum Voltage
";
CM_ SG_ 408 PDM_wpVoltMax "Water Pump Maximum Voltage
";
CM_ SG_ 408 PDM_wpVoltAvg "Water Pump Average Voltage
";
CM_ SG_ 408 PDM_counterMsg408 "Counter Message 408
";
CM_ SG_ 407 PDM_wpCurrentMin "Water Pump Minimum Current
";
CM_ SG_ 407 PDM_wpCurrentMax "Water Pump Maximum Current
";
CM_ SG_ 407 PDM_wpCurrentAvg "Water Pump Average Current
";
CM_ SG_ 407 PDM_counterMsg407 "Counter Message 407
";
CM_ SG_ 406 PDM_fanLeftVoltMin "Left Fan Minimum Voltage
";
CM_ SG_ 406 PDM_fanLeftVoltMax "Left Fan Maximum Voltage
";
CM_ SG_ 406 PDM_fanLeftVoltAvg "Left Fan Average Voltage
";
CM_ SG_ 406 PDM_counterMsg406 "Counter Message 406
";
CM_ SG_ 405 PDM_fanLeftCurrentMin "Left Fan Minimum Current
";
CM_ SG_ 405 PDM_fanLeftCurrentMax "Left Fan Maximum Current
";
CM_ SG_ 405 PDM_fanLeftCurrentAvg "Left Fan Average Current
";
CM_ SG_ 405 PDM_counterMsg405 "Counter Message 405
";
CM_ SG_ 404 PDM_fanRightVoltMin "Right Fan Minimum Voltage
";
CM_ SG_ 404 PDM_fanRightVoltMax "Right Fan Maximum Voltage
";
CM_ SG_ 404 PDM_fanRightVoltAvg "Right Fan Average Voltage
";
CM_ SG_ 404 PDM_counterMsg404 "Counter Message 404
";
CM_ SG_ 403 PDM_fanRightCurrentMin "Right Fan Minimum Current
";
CM_ SG_ 403 PDM_fanRightCurrentMax "Right Fan Maximum Current
";
CM_ SG_ 403 PDM_fanRightCurrentAvg "Right Fan Average Current
";
CM_ SG_ 403 PDM_counterMsg403 "Counter Message 403
";
CM_ SG_ 402 PDM_pdmVoltMin "PDM Minimum Voltage
";
CM_ SG_ 402 PDM_pdmVoltMax "PDM Maximum Voltage
";
CM_ SG_ 402 PDM_pdmVoltAvg "PDM Average Voltage
";
CM_ SG_ 402 PDM_counterMsg402 "Counter Message 302
";
CM_ SG_ 401 PDM_pdmCurrentMin "PDM Minimum Current
";
CM_ SG_ 401 PDM_pdmCurrentMax "PDM Maximum Current
";
CM_ SG_ 401 PDM_pdmCurrentAvg "PDM Average Current
";
CM_ SG_ 401 PDM_counterMsg401 "Counter Message 401
";
CM_ SG_ 400 PDM_vehicleState "fix";
CM_ SG_ 400 PDM_counterMsg400 "Counter Message 400
";
CM_ SG_ 400 PDM_coolingOverrideActive "Cooling Override State
";
CM_ SG_ 400 PDM_brakelightVoltAvg "Brakelight Average Voltage
";
CM_ SG_ 400 PDM_boardTemp "Board Temperature
";
CM_ SG_ 215 BMS_rollingCounter215 "Increments once every 100ms (max value is 255 and rolls over). Can be used to ensure data is updating
";
CM_ SG_ 215 BMS_relayState "Look at utility manual
";
CM_ SG_ 215 BMS_failsafeStatus "Look at utility manual
";
CM_ SG_ 215 BMS_dtcStatus2 "This parameter contains the status of several BMS fault codes. Look at utility manual
";
CM_ SG_ 214 BMS_totalPackCycles "This is the total number of cycles that the battery pack has been put through since the BMS has started keeping track.
";
CM_ SG_ 214 BMS_rollingCounter214 "Increments once every 100ms (max value is 255 and rolls over). Can be used to ensure data is updating
";
CM_ SG_ 214 BMS_populatedCells "This represents the total number of populated (active) cells in the BMS. This can be equal or lower than the Max Cell Number
";
CM_ SG_ 214 BMS_maxCellNumber "The maximum number of cells that the BMS is capable of supporting
";
CM_ SG_ 214 BMS_dtcStatus1 "This parameter contains the status of several BMS fault codes. Look at utility manual
";
CM_ SG_ 213 BMS_rollingCounter213 "Increments once every 100ms (max value is 255 and rolls over). Can be used to ensure data is updating
";
CM_ SG_ 213 BMS_currLimStatus "This value is provided so the reasons for why a current limit either Charge Current Limit or Discharge Current Limit are being reduced by the BMS from the maximum allowable current. Look at utility manual
";
CM_ SG_ 213 BMS_adaptiveTotalCapacity "This is the total number of amphours that the BMS has observed or learned during operation. Over time this will gradually be adjusted as the BMS continues to observe the battery pack
";
CM_ SG_ 213 BMS_adaptiveAmphours "This is the Pack Amphours value equivalent based on the Adaptive Total Capacity metric. This is NOT the total capacity of the battery pack
";
CM_ SG_ 212 BMS_rollingCounter212 "Increments once every 100ms (max value is 255 and rolls over). Can be used to ensure data is updating
";
CM_ SG_ 212 BMS_requestedFanSpeed "This is the current requested speed (0-6) of the battery fan
";
CM_ SG_ 212 BMS_fanVolt "This is the raw voltage measured by the fan monitor circuit. This can be a maximum of 15V
";
CM_ SG_ 212 BMS_fanSpeed "This is the current speed (0-6) of the battery fan. The higher the speed, the faster the fan output should be
";
CM_ SG_ 212 BMS_adaptiveSOC "This is the calculated State of Charge value based on the Adaptive Total Capacity. It is expected for this value to differ, at least slightly, from the overall pack State of Charge parameter as that value is based on the programmed expected capacity
";
CM_ SG_ 211 BMS_rollingCounter211 "Increments once every 100ms (max value is 255 and rolls over). Can be used to ensure data is updating
";
CM_ SG_ 211 BMS_maxPackDCL "This value is the programmed maximum continuous pack Discharge Current Limit
";
CM_ SG_ 211 BMS_maxPackCCL "This value is the programmed maximum continuous pack Charge Current Limit
";
CM_ SG_ 211 BMS_avgPackCurr "This is the AVERAGE current pack amperage value for the battery pack. This will report a constant 0 if no current sensor is selected. The average is taken over the last 1 second of operation so it will lag the instantaneous pack current value
";
CM_ SG_ 210 BMS_rollingCounter210 "Increments once every 100ms (max value is 255 and rolls over). Can be used to ensure data is updating
";
CM_ SG_ 210 BMS_packOpenVolt "This is the current total pack Open Voltage value
";
CM_ SG_ 210 BMS_packDischargeCurrLimkW "This is the pack Discharge Current Limit expressed in kilowatts as opposed to amps
";
CM_ SG_ 210 BMS_packDischargeCurrLim "This is the pack Discharge Current Limit. This value is, by default, reported as a positive value from 0 to whatever the maximum discharge current limit is set to
";
CM_ SG_ 209 BMS_totalPackADC "This is the raw voltage value from the total pack voltage sensor (NOT the sum of all the cell voltages). Only available on BMS models that support the separate total pack sensor
";
CM_ SG_ 209 BMS_rollingCounter209 "Increments once every 100ms (max value is 255 and rolls over). Can be used to ensure data is updating
";
CM_ SG_ 209 BMS_packChargeCurrLimkW "This is the pack Charge Current Limit expressed in kilowatts as opposed to amps
";
CM_ SG_ 209 BMS_packChargeCurrLim "This is the pack Charge Current Limit. The value is, by default, reported as a positive value from 0 to whatever the maximum charge current limit is set to
";
CM_ SG_ 208 BMS_rollingCounter208 "Increments once every 100ms (max value is 255 and rolls over). Can be used to ensure data is updating
";
CM_ SG_ 208 BMS_lowCellVoltID "This value is the ID of the lowest cell voltage measured by the BMS. The value is 1 based (valid range: 1-180)
";
CM_ SG_ 208 BMS_lowCellResistanceID "This value is the ID of the lowest cell resistance measured by the BMS. The value is 1 based (valid range: 1-180)
";
CM_ SG_ 208 BMS_lowCellOpenVoltID "This value is the ID of the lowest cell open (sitting) voltage measured by the BMS. The value is 1 based (valid range: 1-180)
";
CM_ SG_ 208 BMS_highCellVoltID "This value is the ID of the highest cell voltage measured by the BMS. The value is 1 based (valid range: 1-180)
";
CM_ SG_ 208 BMS_highCellResistanceID "This value is the ID of the highest cell resistance measured by the BMS. The value is 1 based (valid range: 1-180)
";
CM_ SG_ 208 BMS_highCellOpenVoltID "This value is the ID of the highest cell open (sitting) voltage measured by the BMS. The value is 1 based (valid range: 1-180)
";
CM_ SG_ 207 BMS_rollingCounter207 "Increments once every 100ms (max value is 255 and rolls over). Can be used to ensure data is updating
";
CM_ SG_ 207 BMS_pwrInputVolt "This is the voltage of the power source that directly powers the BMS (12v-24v nominal for the standard Orion BMS). NOTE: This value will read lower than the actual input voltage seen at the BMS due to internal diode voltage drop
";
CM_ SG_ 207 BMS_minCellVolt "This value is the minimum cell voltage that the BMS is using to limit how low individual cell voltages are allowed to be pulled down to
";
CM_ SG_ 207 BMS_maxCellVolt "This value is the maximum cell voltage that the BMS is using to limit how high individual cell voltages can be. This can be useful for communicating with chargers or charging stations expecting a maximum cell voltage that they are able to charge up to
";
CM_ SG_ 206 BMS_rollingCounter206 "Increments once every 100ms (max value is 255 and rolls over). Can be used to ensure data is updating
";
CM_ SG_ 206 BMS_lowCellInternalResistance "This is the Internal Resistance of the lowest measured cell in the battery pack
";
CM_ SG_ 206 BMS_highCellInternalResistance "This is the Internal Resistance of the highest measured cell in the battery pack
";
CM_ SG_ 206 BMS_avgCellInternalResistance "This is the Internal Resistance of the average measured cell in the battery pack
";
CM_ SG_ 205 BMS_rollingCounter205 "Increments once every 100ms (max value is 255 and rolls over). Can be used to ensure data is updating
";
CM_ SG_ 205 BMS_lowCellOpenVolt "This is the Open Voltage of the lowest measured cell in the battery pack
";
CM_ SG_ 205 BMS_highCellOpenVolt "This is the Open Voltage of the highest measured cell in the battery pack
";
CM_ SG_ 205 BMS_avgCellOpenVolt "This is the Open Voltage of the average measured cell in the battery pack
";
CM_ SG_ 204 BMS_rollingCounter204 "Increments once every 100ms (max value is 255 and rolls over). Can be used to ensure data is updating
";
CM_ SG_ 204 BMS_lowCellVolt "This is the voltage of the lowest measured cell in the battery pack
";
CM_ SG_ 204 BMS_highCellVolt "This is the voltage of the highest measured cell in the battery pack
";
CM_ SG_ 204 BMS_avgCellVolt "This is the voltage of the average measured cell in the battery pack
";
CM_ SG_ 203 BMS_rollingCounter203 "Increments once every 100ms (max value is 255 and rolls over). Can be used to ensure data is updating
";
CM_ SG_ 203 BMS_lowestThermistorID "This is the ID of the lowest temperature thermistor being sensed by the BMS. The lowest possible value is 1
";
CM_ SG_ 203 BMS_lowestTemp "This signed value is the lowest temperature measured in the battery pack
";
CM_ SG_ 203 BMS_internalTemp "This signed value is the internal temperature measured by the BMS (specifically, it is the temperature of the heatsink case)
";
CM_ SG_ 203 BMS_highestThermistorID "This is the ID of the highest temperature thermistor being sensed by the BMS. The lowest possible value is 1
";
CM_ SG_ 203 BMS_highestTemp "This signed value is the highest temperature measured in the battery pack
";
CM_ SG_ 203 BMS_avgTemp "This signed value is the average temperature measured in the battery back by the thermistors
";
CM_ SG_ 202 BMS_rollingCounter202 "Increments once every 100ms (max value is 255 and rolls over). Can be used to ensure data is updating
";
CM_ SG_ 202 BMS_packSOH "This is the total state of health for the battery pack
";
CM_ SG_ 202 BMS_packResistance "This is the combined measured internal resistance for the entire battery pack
";
CM_ SG_ 202 BMS_packDOD "This value represents the total pack depth of discharge (that is, the total percent of the battery that has been discharged to this point). This value does not account for any Drift
";
CM_ SG_ 202 BMS_packAmphours "This is the calculated number of amphours remaining in the battery pack. This is used in part to calculate State of Charge
";
CM_ SG_ 201 BMS_rollingCounter201 "Increments once every 100ms (max value is 255 and rolls over). Can be used to ensure data is updating
";
CM_ SG_ 201 BMS_packSummedVolt "This value is the sum of all the cells being monitored by the BMS and represents the overall pack voltage. It is essentially identical to the Pack Voltage value, except that it is reported wit ha higher resolution (0.01V versus 0.1V)
";
CM_ SG_ 201 BMS_minPackVolt "This value is the mainimum pack voltage that the BMS is using to limit how low the pack voltage is allowed to be pulled down to
";
CM_ SG_ 201 BMS_maxPackVolt "This value is the maximum pack voltage that the BMS is using to limit how high the pack voltage can be. This can be useful for communicating with chargers or charging stations expecting a maximum pack voltage value they are able to charge up to
";
CM_ SG_ 200 BMS_rollingCounter200 "Increments once every 100ms (max value is 255 and rolls over). Can be used to ensure data is updating
";
CM_ SG_ 200 BMS_packVolt "This is the instantaneous total pack voltage value
";
CM_ SG_ 200 BMS_packSOC "This is the pack State of Charge
";
CM_ SG_ 200 BMS_packCurr "This is the current pack amperage value for the battery pack. This will report a constant 0 if no current sensor is selected
";
CM_ SG_ 150 VCU_throttlePosition2 "TPS2";
CM_ SG_ 150 VCU_throttlePosition1 "TPS1";
CM_ SG_ 150 VCU_throttlePosition "Final throttle position";
CM_ SG_ 150 VCU_counterMsg150 "Counter Message 150
";
BA_DEF_  "BusType" STRING ;
BA_DEF_DEF_  "BusType" "CAN";
VAL_ 152 VCU_mainMinusContactorState 2 "Open" 1 "Close" 0 "Faulted" ;
VAL_ 152 VCU_mainPlusContactorState 2 "Open" 1 "Close" 0 "Faulted" ;
VAL_ 152 VCU_prechargeContactorState 2 "Open" 1 "Close" 0 "Faulted" ;
VAL_ 152 VCU_dischargeContactorState 2 "Open" 1 "Close" 0 "Faulted" ;
VAL_ 152 VCU_vehicleState 8 "Faulted" 7 "ReadyToMove" 6 "Standby" 5 "PrechargeComplete" 4 "PrechargeTimeout" 3 "Precharge" 2 "PrechargeReady" 1 "StartDelay" 0 "Off" ;
